AUTOSAR XML (schema 4-0-3)
standard types defined: Boolean, UInt16, UInt32
package /AUTOSAR_Platform/DataConstrs
  range DC_Boolean: raw 0..1
  range DC_UInt16: raw 0..65535
package /PATAC/Facility/DataTypes/Implementation
  compu method COMPU_Boolean: 0=FALSE, 1=TRUE
  unit NoUnit: factor-si-to-unit=1, offset-si-to-unit=0
package /PATAC/MSM/ComponentTypes
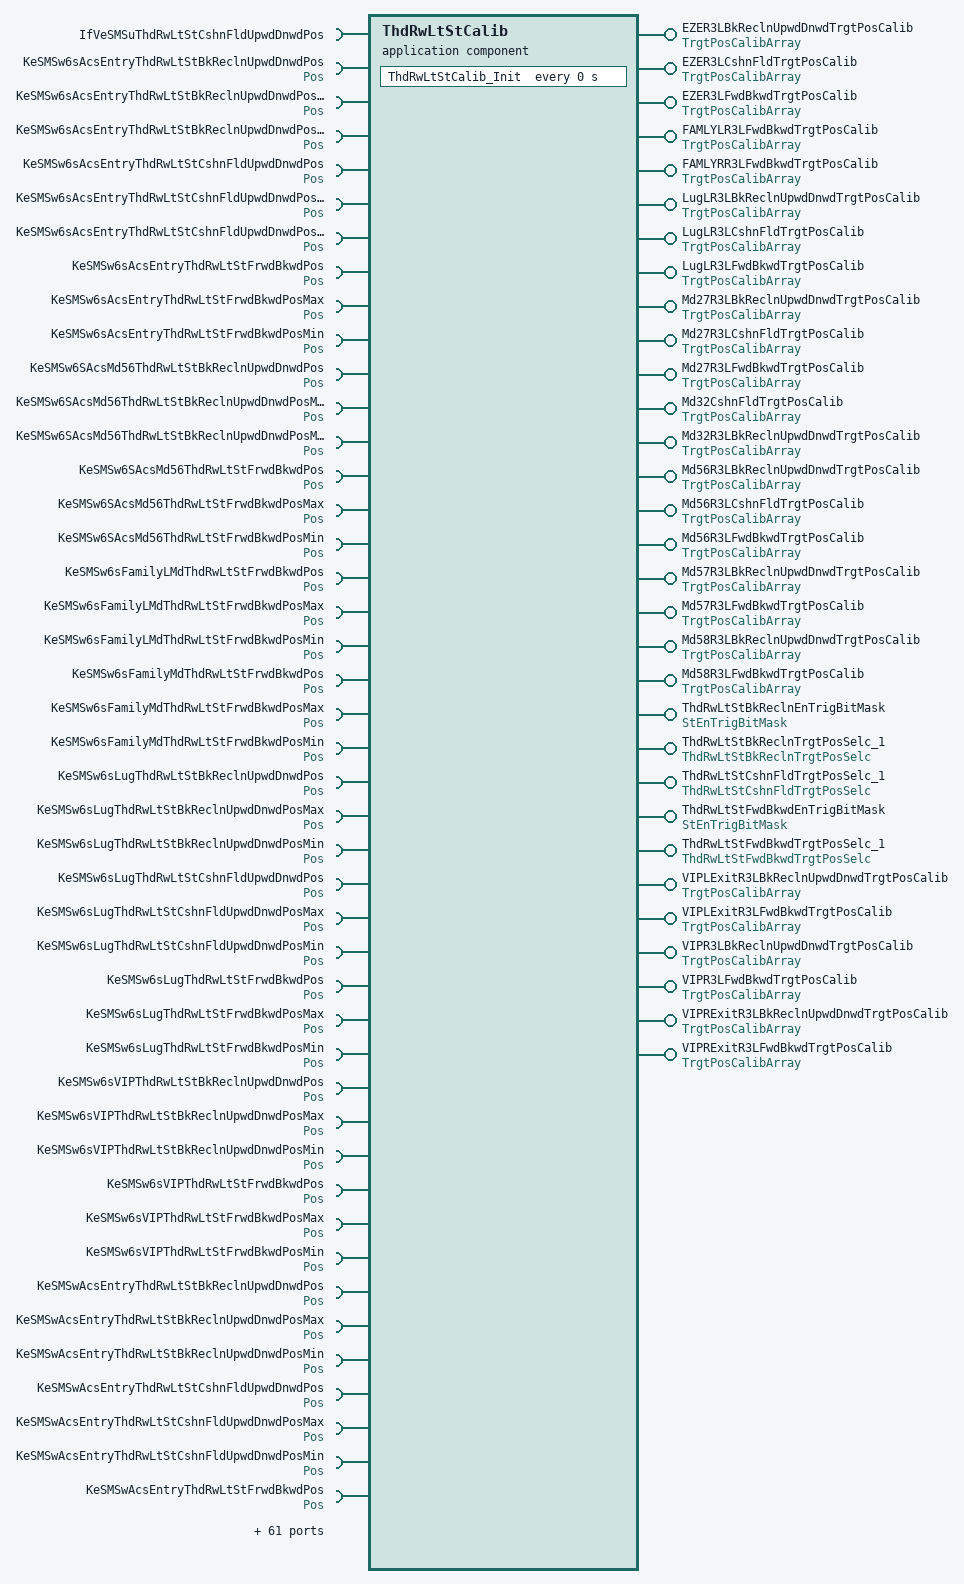
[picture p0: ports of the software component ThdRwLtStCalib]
  application sw component type ThdRwLtStCalib
    31 x provide port:
      EZER3LBkReclnUpwdDnwdTrgtPosCalib: nonqueued-sender-com-spec{data-element=TrgtPosArray, init-value=[4095, 4095, 4095]}, provided-interface=TrgtPosCalibArray
      EZER3LCshnFldTrgtPosCalib: nonqueued-sender-com-spec{data-element=TrgtPosArray, init-value=[4095, 4095, 4095]}, provided-interface=TrgtPosCalibArray
      EZER3LFwdBkwdTrgtPosCalib: nonqueued-sender-com-spec{data-element=TrgtPosArray, init-value=[4095, 4095, 4095]}, provided-interface=TrgtPosCalibArray
      FAMLYLR3LFwdBkwdTrgtPosCalib: nonqueued-sender-com-spec{data-element=TrgtPosArray, init-value=[4095, 4095, 4095]}, provided-interface=TrgtPosCalibArray
      FAMLYRR3LFwdBkwdTrgtPosCalib: nonqueued-sender-com-spec{data-element=TrgtPosArray, init-value=[4095, 4095, 4095]}, provided-interface=TrgtPosCalibArray
      LugLR3LBkReclnUpwdDnwdTrgtPosCalib: nonqueued-sender-com-spec{data-element=TrgtPosArray, init-value=[4095, 4095, 4095]}, provided-interface=TrgtPosCalibArray
      LugLR3LCshnFldTrgtPosCalib: nonqueued-sender-com-spec{data-element=TrgtPosArray, init-value=[4095, 4095, 4095]}, provided-interface=TrgtPosCalibArray
      LugLR3LFwdBkwdTrgtPosCalib: nonqueued-sender-com-spec{data-element=TrgtPosArray, init-value=[4095, 4095, 4095]}, provided-interface=TrgtPosCalibArray
      Md27R3LBkReclnUpwdDnwdTrgtPosCalib: nonqueued-sender-com-spec{data-element=TrgtPosArray, init-value=[4095, 4095, 4095]}, provided-interface=TrgtPosCalibArray
      Md27R3LCshnFldTrgtPosCalib: nonqueued-sender-com-spec{data-element=TrgtPosArray, init-value=[4095, 4095, 4095]}, provided-interface=TrgtPosCalibArray
      Md27R3LFwdBkwdTrgtPosCalib: nonqueued-sender-com-spec{data-element=TrgtPosArray, init-value=[4095, 4095, 4095]}, provided-interface=TrgtPosCalibArray
      Md32CshnFldTrgtPosCalib: nonqueued-sender-com-spec{data-element=TrgtPosArray, init-value=[4095, 4095, 4095]}, provided-interface=TrgtPosCalibArray
      Md32R3LBkReclnUpwdDnwdTrgtPosCalib: nonqueued-sender-com-spec{data-element=TrgtPosArray, init-value=[4095, 4095, 4095]}, provided-interface=TrgtPosCalibArray
      Md56R3LBkReclnUpwdDnwdTrgtPosCalib: nonqueued-sender-com-spec{data-element=TrgtPosArray, init-value=[4095, 4095, 4095]}, provided-interface=TrgtPosCalibArray
      Md56R3LCshnFldTrgtPosCalib: nonqueued-sender-com-spec{data-element=TrgtPosArray, init-value=[4095, 4095, 4095]}, provided-interface=TrgtPosCalibArray
      Md56R3LFwdBkwdTrgtPosCalib: nonqueued-sender-com-spec{data-element=TrgtPosArray, init-value=[4095, 4095, 4095]}, provided-interface=TrgtPosCalibArray
      Md57R3LBkReclnUpwdDnwdTrgtPosCalib: nonqueued-sender-com-spec{data-element=TrgtPosArray, init-value=[4095, 4095, 4095]}, provided-interface=TrgtPosCalibArray
      Md57R3LFwdBkwdTrgtPosCalib: nonqueued-sender-com-spec{data-element=TrgtPosArray, init-value=[4095, 4095, 4095]}, provided-interface=TrgtPosCalibArray
      Md58R3LBkReclnUpwdDnwdTrgtPosCalib: nonqueued-sender-com-spec{data-element=TrgtPosArray, init-value=[4095, 4095, 4095]}, provided-interface=TrgtPosCalibArray
      Md58R3LFwdBkwdTrgtPosCalib: nonqueued-sender-com-spec{data-element=TrgtPosArray, init-value=[4095, 4095, 4095]}, provided-interface=TrgtPosCalibArray
      ThdRwLtStBkReclnEnTrigBitMask: nonqueued-sender-com-spec{data-element=StEnTrigBitMask/Val, init-value=0}, provided-interface=StEnTrigBitMask
      ThdRwLtStBkReclnTrgtPosSelc_1: server-com-spec{operation=ThdRwLtStBkReclnTrgtPosSelc/Cal, queue-length=1}, provided-interface=ThdRwLtStBkReclnTrgtPosSelc
      ThdRwLtStCshnFldTrgtPosSelc_1: server-com-spec{operation=ThdRwLtStCshnFldTrgtPosSelc/Cal, queue-length=1}, provided-interface=ThdRwLtStCshnFldTrgtPosSelc
      ThdRwLtStFwdBkwdEnTrigBitMask: nonqueued-sender-com-spec{data-element=StEnTrigBitMask/Val, init-value=0}, provided-interface=StEnTrigBitMask
      ThdRwLtStFwdBkwdTrgtPosSelc_1: server-com-spec{operation=ThdRwLtStFwdBkwdTrgtPosSelc/Cal, queue-length=1}, provided-interface=ThdRwLtStFwdBkwdTrgtPosSelc
      VIPLExitR3LBkReclnUpwdDnwdTrgtPosCalib: nonqueued-sender-com-spec{data-element=TrgtPosArray, init-value=[4095, 4095, 4095]}, provided-interface=TrgtPosCalibArray
      VIPLExitR3LFwdBkwdTrgtPosCalib: nonqueued-sender-com-spec{data-element=TrgtPosArray, init-value=[4095, 4095, 4095]}, provided-interface=TrgtPosCalibArray
      VIPR3LBkReclnUpwdDnwdTrgtPosCalib: nonqueued-sender-com-spec{data-element=TrgtPosArray, init-value=[4095, 4095, 4095]}, provided-interface=TrgtPosCalibArray
      VIPR3LFwdBkwdTrgtPosCalib: nonqueued-sender-com-spec{data-element=TrgtPosArray, init-value=[4095, 4095, 4095]}, provided-interface=TrgtPosCalibArray
      VIPRExitR3LBkReclnUpwdDnwdTrgtPosCalib: nonqueued-sender-com-spec{data-element=TrgtPosArray, init-value=[4095, 4095, 4095]}, provided-interface=TrgtPosCalibArray
      VIPRExitR3LFwdBkwdTrgtPosCalib: nonqueued-sender-com-spec{data-element=TrgtPosArray, init-value=[4095, 4095, 4095]}, provided-interface=TrgtPosCalibArray
    105 x require port:
      IfVeSMSuThdRwLtStCshnFldUpwdDnwdPos: nonqueued-receiver-com-spec{data-element=IfVeSMSuThdRwLtStCshnFldUpwdDnwdPos/Val, filter=data-filter-type=ALWAYS, init-value=0}, required-interface=IfVeSMSuThdRwLtStCshnFldUpwdDnwdPos
      KeSMSw6sAcsEntryThdRwLtStBkReclnUpwdDnwdPos: parameter-require-com-spec{init-value=2080, parameter=Pos/Val}, required-interface=Pos
      KeSMSw6sAcsEntryThdRwLtStBkReclnUpwdDnwdPosMax: parameter-require-com-spec{init-value=2095, parameter=Pos/Val}, required-interface=Pos
      KeSMSw6sAcsEntryThdRwLtStBkReclnUpwdDnwdPosMin: parameter-require-com-spec{init-value=0, parameter=Pos/Val}, required-interface=Pos
      KeSMSw6sAcsEntryThdRwLtStCshnFldUpwdDnwdPos: parameter-require-com-spec{init-value=0, parameter=Pos/Val}, required-interface=Pos
      KeSMSw6sAcsEntryThdRwLtStCshnFldUpwdDnwdPosMax: parameter-require-com-spec{init-value=0, parameter=Pos/Val}, required-interface=Pos
      KeSMSw6sAcsEntryThdRwLtStCshnFldUpwdDnwdPosMin: parameter-require-com-spec{init-value=0, parameter=Pos/Val}, required-interface=Pos
      KeSMSw6sAcsEntryThdRwLtStFrwdBkwdPos: parameter-require-com-spec{init-value=2760, parameter=Pos/Val}, required-interface=Pos
      KeSMSw6sAcsEntryThdRwLtStFrwdBkwdPosMax: parameter-require-com-spec{init-value=4000, parameter=Pos/Val}, required-interface=Pos
      KeSMSw6sAcsEntryThdRwLtStFrwdBkwdPosMin: parameter-require-com-spec{init-value=2760, parameter=Pos/Val}, required-interface=Pos
      KeSMSw6SAcsMd56ThdRwLtStBkReclnUpwdDnwdPos: parameter-require-com-spec{init-value=0, parameter=Pos/Val}, required-interface=Pos
      KeSMSw6SAcsMd56ThdRwLtStBkReclnUpwdDnwdPosMax: parameter-require-com-spec{init-value=0, parameter=Pos/Val}, required-interface=Pos
      KeSMSw6SAcsMd56ThdRwLtStBkReclnUpwdDnwdPosMin: parameter-require-com-spec{init-value=0, parameter=Pos/Val}, required-interface=Pos
      KeSMSw6SAcsMd56ThdRwLtStFrwdBkwdPos: parameter-require-com-spec{init-value=0, parameter=Pos/Val}, required-interface=Pos
      KeSMSw6SAcsMd56ThdRwLtStFrwdBkwdPosMax: parameter-require-com-spec{init-value=0, parameter=Pos/Val}, required-interface=Pos
      KeSMSw6SAcsMd56ThdRwLtStFrwdBkwdPosMin: parameter-require-com-spec{init-value=0, parameter=Pos/Val}, required-interface=Pos
      KeSMSw6sFamilyLMdThdRwLtStFrwdBkwdPos: parameter-require-com-spec{init-value=0, parameter=Pos/Val}, required-interface=Pos
      KeSMSw6sFamilyLMdThdRwLtStFrwdBkwdPosMax: parameter-require-com-spec{init-value=0, parameter=Pos/Val}, required-interface=Pos
      KeSMSw6sFamilyLMdThdRwLtStFrwdBkwdPosMin: parameter-require-com-spec{init-value=0, parameter=Pos/Val}, required-interface=Pos
      KeSMSw6sFamilyMdThdRwLtStFrwdBkwdPos: parameter-require-com-spec{init-value=0, parameter=Pos/Val}, required-interface=Pos
      KeSMSw6sFamilyMdThdRwLtStFrwdBkwdPosMax: parameter-require-com-spec{init-value=0, parameter=Pos/Val}, required-interface=Pos
      KeSMSw6sFamilyMdThdRwLtStFrwdBkwdPosMin: parameter-require-com-spec{init-value=0, parameter=Pos/Val}, required-interface=Pos
      KeSMSw6sLugThdRwLtStBkReclnUpwdDnwdPos: parameter-require-com-spec{init-value=0, parameter=Pos/Val}, required-interface=Pos
      KeSMSw6sLugThdRwLtStBkReclnUpwdDnwdPosMax: parameter-require-com-spec{init-value=0, parameter=Pos/Val}, required-interface=Pos
      KeSMSw6sLugThdRwLtStBkReclnUpwdDnwdPosMin: parameter-require-com-spec{init-value=0, parameter=Pos/Val}, required-interface=Pos
      KeSMSw6sLugThdRwLtStCshnFldUpwdDnwdPos: parameter-require-com-spec{init-value=30, parameter=Pos/Val}, required-interface=Pos
      KeSMSw6sLugThdRwLtStCshnFldUpwdDnwdPosMax: parameter-require-com-spec{init-value=40, parameter=Pos/Val}, required-interface=Pos
      KeSMSw6sLugThdRwLtStCshnFldUpwdDnwdPosMin: parameter-require-com-spec{init-value=20, parameter=Pos/Val}, required-interface=Pos
      KeSMSw6sLugThdRwLtStFrwdBkwdPos: parameter-require-com-spec{init-value=0, parameter=Pos/Val}, required-interface=Pos
      KeSMSw6sLugThdRwLtStFrwdBkwdPosMax: parameter-require-com-spec{init-value=0, parameter=Pos/Val}, required-interface=Pos
      KeSMSw6sLugThdRwLtStFrwdBkwdPosMin: parameter-require-com-spec{init-value=0, parameter=Pos/Val}, required-interface=Pos
      KeSMSw6sVIPThdRwLtStBkReclnUpwdDnwdPos: parameter-require-com-spec{init-value=0, parameter=Pos/Val}, required-interface=Pos
      KeSMSw6sVIPThdRwLtStBkReclnUpwdDnwdPosMax: parameter-require-com-spec{init-value=0, parameter=Pos/Val}, required-interface=Pos
      KeSMSw6sVIPThdRwLtStBkReclnUpwdDnwdPosMin: parameter-require-com-spec{init-value=0, parameter=Pos/Val}, required-interface=Pos
      KeSMSw6sVIPThdRwLtStFrwdBkwdPos: parameter-require-com-spec{init-value=4000, parameter=Pos/Val}, required-interface=Pos
      KeSMSw6sVIPThdRwLtStFrwdBkwdPosMax: parameter-require-com-spec{init-value=4000, parameter=Pos/Val}, required-interface=Pos
      KeSMSw6sVIPThdRwLtStFrwdBkwdPosMin: parameter-require-com-spec{init-value=4000, parameter=Pos/Val}, required-interface=Pos
      KeSMSwAcsEntryThdRwLtStBkReclnUpwdDnwdPos: parameter-require-com-spec{init-value=2080, parameter=Pos/Val}, required-interface=Pos
      KeSMSwAcsEntryThdRwLtStBkReclnUpwdDnwdPosMax: parameter-require-com-spec{init-value=2095, parameter=Pos/Val}, required-interface=Pos
      KeSMSwAcsEntryThdRwLtStBkReclnUpwdDnwdPosMin: parameter-require-com-spec{init-value=0, parameter=Pos/Val}, required-interface=Pos
      KeSMSwAcsEntryThdRwLtStCshnFldUpwdDnwdPos: parameter-require-com-spec{init-value=0, parameter=Pos/Val}, required-interface=Pos
      KeSMSwAcsEntryThdRwLtStCshnFldUpwdDnwdPosMax: parameter-require-com-spec{init-value=0, parameter=Pos/Val}, required-interface=Pos
      KeSMSwAcsEntryThdRwLtStCshnFldUpwdDnwdPosMin: parameter-require-com-spec{init-value=0, parameter=Pos/Val}, required-interface=Pos
      KeSMSwAcsEntryThdRwLtStFrwdBkwdPos: parameter-require-com-spec{init-value=2760, parameter=Pos/Val}, required-interface=Pos
      KeSMSwAcsEntryThdRwLtStFrwdBkwdPosMax: parameter-require-com-spec{init-value=4000, parameter=Pos/Val}, required-interface=Pos
      KeSMSwAcsEntryThdRwLtStFrwdBkwdPosMin: parameter-require-com-spec{init-value=2760, parameter=Pos/Val}, required-interface=Pos
      KeSMSwAcsMd32ThdRwLtBkReclnUpwdDnwdPos: parameter-require-com-spec{init-value=2080, parameter=Pos/Val}, required-interface=Pos
      KeSMSwAcsMd32ThdRwLtBkReclnUpwdDnwdPosMax: parameter-require-com-spec{init-value=2080, parameter=Pos/Val}, required-interface=Pos
      KeSMSwAcsMd32ThdRwLtBkReclnUpwdDnwdPosMin: parameter-require-com-spec{init-value=2080, parameter=Pos/Val}, required-interface=Pos
      KeSMSwAcsMd32ThdRwLtFldUpwdDnwdPos: parameter-require-com-spec{init-value=0, parameter=Pos/Val}, required-interface=Pos
      KeSMSwAcsMd32ThdRwLtFldUpwdDnwdPosMax: parameter-require-com-spec{init-value=0, parameter=Pos/Val}, required-interface=Pos
      KeSMSwAcsMd32ThdRwLtFldUpwdDnwdPosMin: parameter-require-com-spec{init-value=0, parameter=Pos/Val}, required-interface=Pos
      KeSMSwAcsMd56ThdRwLtStBkReclnUpwdDnwdPos: parameter-require-com-spec{init-value=0, parameter=Pos/Val}, required-interface=Pos
      KeSMSwAcsMd56ThdRwLtStBkReclnUpwdDnwdPosMax: parameter-require-com-spec{init-value=0, parameter=Pos/Val}, required-interface=Pos
      KeSMSwAcsMd56ThdRwLtStBkReclnUpwdDnwdPosMin: parameter-require-com-spec{init-value=0, parameter=Pos/Val}, required-interface=Pos
      KeSMSwAcsMd56ThdRwLtStCshnFldUpwdDnwdPos: parameter-require-com-spec{init-value=0, parameter=Pos/Val}, required-interface=Pos
      KeSMSwAcsMd56ThdRwLtStCshnFldUpwdDnwdPosMax: parameter-require-com-spec{init-value=0, parameter=Pos/Val}, required-interface=Pos
      KeSMSwAcsMd56ThdRwLtStCshnFldUpwdDnwdPosMin: parameter-require-com-spec{init-value=0, parameter=Pos/Val}, required-interface=Pos
      KeSMSwAcsMd56ThdRwLtStFrwdBkwdPos: parameter-require-com-spec{init-value=0, parameter=Pos/Val}, required-interface=Pos
      KeSMSwAcsMd56ThdRwLtStFrwdBkwdPosMax: parameter-require-com-spec{init-value=0, parameter=Pos/Val}, required-interface=Pos
      KeSMSwAcsMd56ThdRwLtStFrwdBkwdPosMin: parameter-require-com-spec{init-value=0, parameter=Pos/Val}, required-interface=Pos
      KeSMSwAcsMd57ThdRwLtStBkReclnUpwdDnwdPos: parameter-require-com-spec{init-value=0, parameter=Pos/Val}, required-interface=Pos
      KeSMSwAcsMd57ThdRwLtStBkReclnUpwdDnwdPosMax: parameter-require-com-spec{init-value=0, parameter=Pos/Val}, required-interface=Pos
      KeSMSwAcsMd57ThdRwLtStBkReclnUpwdDnwdPosMin: parameter-require-com-spec{init-value=0, parameter=Pos/Val}, required-interface=Pos
      KeSMSwAcsMd57ThdRwLtStFrwdBkwdPos: parameter-require-com-spec{init-value=0, parameter=Pos/Val}, required-interface=Pos
      KeSMSwAcsMd57ThdRwLtStFrwdBkwdPosMax: parameter-require-com-spec{init-value=0, parameter=Pos/Val}, required-interface=Pos
      KeSMSwAcsMd57ThdRwLtStFrwdBkwdPosMin: parameter-require-com-spec{init-value=0, parameter=Pos/Val}, required-interface=Pos
      KeSMSwAcsMd6ThdRwLtStBkReclnUpwdDnwdPos: parameter-require-com-spec{init-value=0, parameter=Pos/Val}, required-interface=Pos
      KeSMSwAcsMd6ThdRwLtStBkReclnUpwdDnwdPosMax: parameter-require-com-spec{init-value=0, parameter=Pos/Val}, required-interface=Pos
      KeSMSwAcsMd6ThdRwLtStBkReclnUpwdDnwdPosMin: parameter-require-com-spec{init-value=0, parameter=Pos/Val}, required-interface=Pos
      KeSMSwAcsMd6ThdRwLtStCshnFldUpwdDnwdPos: parameter-require-com-spec{init-value=0, parameter=Pos/Val}, required-interface=Pos
      KeSMSwAcsMd6ThdRwLtStCshnFldUpwdDnwdPosMax: parameter-require-com-spec{init-value=0, parameter=Pos/Val}, required-interface=Pos
      KeSMSwAcsMd6ThdRwLtStCshnFldUpwdDnwdPosMin: parameter-require-com-spec{init-value=0, parameter=Pos/Val}, required-interface=Pos
      KeSMSwAcsMd6ThdRwLtStFrwdBkwdPos: parameter-require-com-spec{init-value=0, parameter=Pos/Val}, required-interface=Pos
      KeSMSwAcsMd6ThdRwLtStFrwdBkwdPosMax: parameter-require-com-spec{init-value=0, parameter=Pos/Val}, required-interface=Pos
      KeSMSwAcsMd6ThdRwLtStFrwdBkwdPosMin: parameter-require-com-spec{init-value=0, parameter=Pos/Val}, required-interface=Pos
      KeSMSwFamilyLMdThdRwLtStFrwdBkwdPos: parameter-require-com-spec{init-value=0, parameter=Pos/Val}, required-interface=Pos
      KeSMSwFamilyLMdThdRwLtStFrwdBkwdPosMax: parameter-require-com-spec{init-value=0, parameter=Pos/Val}, required-interface=Pos
      KeSMSwFamilyLMdThdRwLtStFrwdBkwdPosMin: parameter-require-com-spec{init-value=0, parameter=Pos/Val}, required-interface=Pos
      KeSMSwFamilyMdThdRwLtStFrwdBkwdPos: parameter-require-com-spec{init-value=0, parameter=Pos/Val}, required-interface=Pos
      KeSMSwFamilyMdThdRwLtStFrwdBkwdPosMax: parameter-require-com-spec{init-value=0, parameter=Pos/Val}, required-interface=Pos
      KeSMSwFamilyMdThdRwLtStFrwdBkwdPosMin: parameter-require-com-spec{init-value=0, parameter=Pos/Val}, required-interface=Pos
      KeSMSwLugThdRwLtStBkReclnUpwdDnwdPos: parameter-require-com-spec{init-value=0, parameter=Pos/Val}, required-interface=Pos
      KeSMSwLugThdRwLtStBkReclnUpwdDnwdPosMax: parameter-require-com-spec{init-value=0, parameter=Pos/Val}, required-interface=Pos
      KeSMSwLugThdRwLtStBkReclnUpwdDnwdPosMin: parameter-require-com-spec{init-value=0, parameter=Pos/Val}, required-interface=Pos
      KeSMSwLugThdRwLtStCshnFldUpwdDnwdPos: parameter-require-com-spec{init-value=30, parameter=Pos/Val}, required-interface=Pos
      KeSMSwLugThdRwLtStCshnFldUpwdDnwdPosMax: parameter-require-com-spec{init-value=0, parameter=Pos/Val}, required-interface=Pos
      KeSMSwLugThdRwLtStCshnFldUpwdDnwdPosMin: parameter-require-com-spec{init-value=20, parameter=Pos/Val}, required-interface=Pos
      KeSMSwLugThdRwLtStFrwdBkwdPos: parameter-require-com-spec{init-value=0, parameter=Pos/Val}, required-interface=Pos
      KeSMSwLugThdRwLtStFrwdBkwdPosMax: parameter-require-com-spec{init-value=0, parameter=Pos/Val}, required-interface=Pos
      KeSMSwLugThdRwLtStFrwdBkwdPosMin: parameter-require-com-spec{init-value=0, parameter=Pos/Val}, required-interface=Pos
      KeSMSwThdRwLtStBkReclnEnTrigBitMask: parameter-require-com-spec{init-value=6153, parameter=StEnTrigBitMask/Val}, required-interface=StEnTrigBitMask
      KeSMSwThdRwLtStBkReclnEnTrigBitMask6s: parameter-require-com-spec{init-value=6153, parameter=StEnTrigBitMask/Val}, required-interface=StEnTrigBitMask
      KeSMSwThdRwLtStFwdBkwdEnTrigBitMask: parameter-require-com-spec{init-value=6153, parameter=StEnTrigBitMask/Val}, required-interface=StEnTrigBitMask
      KeSMSwThdRwLtStFwdBkwdEnTrigBitMask6s: parameter-require-com-spec{init-value=6153, parameter=StEnTrigBitMask/Val}, required-interface=StEnTrigBitMask
      KeSMSwVIPThdRwLtStBkReclnUpwdDnwdPos: parameter-require-com-spec{init-value=0, parameter=Pos/Val}, required-interface=Pos
      KeSMSwVIPThdRwLtStBkReclnUpwdDnwdPosMax: parameter-require-com-spec{init-value=0, parameter=Pos/Val}, required-interface=Pos
      KeSMSwVIPThdRwLtStBkReclnUpwdDnwdPosMin: parameter-require-com-spec{init-value=0, parameter=Pos/Val}, required-interface=Pos
      KeSMSwVIPThdRwLtStFrwdBkwdPos: parameter-require-com-spec{init-value=4000, parameter=Pos/Val}, required-interface=Pos
      KeSMSwVIPThdRwLtStFrwdBkwdPosMax: parameter-require-com-spec{init-value=4000, parameter=Pos/Val}, required-interface=Pos
      KeSMSwVIPThdRwLtStFrwdBkwdPosMin: parameter-require-com-spec{init-value=4000, parameter=Pos/Val}, required-interface=Pos
      Md58TrgtPos: required-com-specs=[Md58TrgtPos/Get, Md58TrgtPos/Set], required-interface=Md58TrgtPos
      StNumFlg: required-interface=StNumFlg
        required-com-specs:
          data-element=Is4s, filter=data-filter-type=ALWAYS, init-value=0
          data-element=Is6s, filter=data-filter-type=ALWAYS, init-value=0
          data-element=Is6s7s, filter=data-filter-type=ALWAYS, init-value=0
          data-element=Is7s, filter=data-filter-type=ALWAYS, init-value=0
      VIPLExit557TrgtPos: required-com-specs=[VIPLExit557TrgtPos/Get, VIPLExit557TrgtPos/Set], required-interface=VIPLExit557TrgtPos
      VIPRExit557TrgtPos: required-com-specs=[VIPRExit557TrgtPos/Get, VIPRExit557TrgtPos/Set], required-interface=VIPRExit557TrgtPos
    behavior ThdRwLtStCalib_InternalBehavior
      operation invoked event OIT_ThdRwLtStBkReclnTrgtPosSelc_1_Cal_ThdRwLtStBkReclnTrgtPosSelc_1_Cal: start-on-event=ThdRwLtStBkReclnTrgtPosSelc_1_Cal, operation=ThdRwLtStBkReclnTrgtPosSelc_1.Cal
      timing event ThdRwLtStCalib_InitEvent: start-on-event=ThdRwLtStCalib_Init, period=0
      operation invoked event OIT_ThdRwLtStCshnFldTrgtPosSelc_1_Cal_ThdRwLtStCshnFldTrgtPosSelc_1_Cal: start-on-event=ThdRwLtStCshnFldTrgtPosSelc_1_Cal, operation=ThdRwLtStCshnFldTrgtPosSelc_1.Cal
      operation invoked event OIT_ThdRwLtStFwdBkwdTrgtPosSelc_1_Cal_ThdRwLtStFwdBkwdTrgtPosSelc_1_Cal: start-on-event=ThdRwLtStFwdBkwdTrgtPosSelc_1_Cal, operation=ThdRwLtStFwdBkwdTrgtPosSelc_1.Cal
      4 x runnable:
        ThdRwLtStBkReclnTrgtPosSelc_1_Cal
          data-receive-point-by-arguments:
            4 x access:
              REC_StNumFlg_Is4s: accessed-variable=StNumFlg.Is4s
              REC_StNumFlg_Is6s: accessed-variable=StNumFlg.Is6s
              REC_StNumFlg_Is6s7s: accessed-variable=StNumFlg.Is6s7s
              REC_StNumFlg_Is7s: accessed-variable=StNumFlg.Is7s
          data-send-points:
            14 x access:
              SEND_EZER3LBkReclnUpwdDnwdTrgtPosCalib_TrgtPosArray: accessed-variable=EZER3LBkReclnUpwdDnwdTrgtPosCalib.TrgtPosArray
              SEND_LugLR3LBkReclnUpwdDnwdTrgtPosCalib_TrgtPosArray: accessed-variable=LugLR3LBkReclnUpwdDnwdTrgtPosCalib.TrgtPosArray
              SEND_Md27R3LBkReclnUpwdDnwdTrgtPosCalib_TrgtPosArray: accessed-variable=Md27R3LBkReclnUpwdDnwdTrgtPosCalib.TrgtPosArray
              SEND_Md32R3LBkReclnUpwdDnwdTrgtPosCalib_TrgtPosArray: accessed-variable=Md32R3LBkReclnUpwdDnwdTrgtPosCalib.TrgtPosArray
              SEND_Md{56..58}R3LBkReclnUpwdDnwdTrgtPosCalib_TrgtPosArray: accessed-variable=Md{56..58}R3LBkReclnUpwdDnwdTrgtPosCalib.TrgtPosArray
              SEND_Md58R3LFwdBkwdTrgtPosCalib_TrgtPosArray: accessed-variable=Md58R3LFwdBkwdTrgtPosCalib.TrgtPosArray
              SEND_ThdRwLtStBkReclnEnTrigBitMask_Val: accessed-variable=ThdRwLtStBkReclnEnTrigBitMask.Val
              SEND_VIPLExitR3LBkReclnUpwdDnwdTrgtPosCalib_TrgtPosArray: accessed-variable=VIPLExitR3LBkReclnUpwdDnwdTrgtPosCalib.TrgtPosArray
              SEND_VIPLExitR3LFwdBkwdTrgtPosCalib_TrgtPosArray: accessed-variable=VIPLExitR3LFwdBkwdTrgtPosCalib.TrgtPosArray
              SEND_VIPR3LBkReclnUpwdDnwdTrgtPosCalib_TrgtPosArray: accessed-variable=VIPR3LBkReclnUpwdDnwdTrgtPosCalib.TrgtPosArray
              SEND_VIPRExitR3LBkReclnUpwdDnwdTrgtPosCalib_TrgtPosArray: accessed-variable=VIPRExitR3LBkReclnUpwdDnwdTrgtPosCalib.TrgtPosArray
              SEND_VIPRExitR3LFwdBkwdTrgtPosCalib_TrgtPosArray: accessed-variable=VIPRExitR3LFwdBkwdTrgtPosCalib.TrgtPosArray
          100 x parameter access:
            PA_KeSMSw6sAcsEntryThdRwLtStBkReclnUpwdDnwdPos_Val: accessed-parameter=KeSMSw6sAcsEntryThdRwLtStBkReclnUpwdDnwdPos.Val
            PA_KeSMSw6sAcsEntryThdRwLtStBkReclnUpwdDnwdPosMax_Val: accessed-parameter=KeSMSw6sAcsEntryThdRwLtStBkReclnUpwdDnwdPosMax.Val
            PA_KeSMSw6sAcsEntryThdRwLtStBkReclnUpwdDnwdPosMin_Val: accessed-parameter=KeSMSw6sAcsEntryThdRwLtStBkReclnUpwdDnwdPosMin.Val
            PA_KeSMSw6sAcsEntryThdRwLtStCshnFldUpwdDnwdPos_Val: accessed-parameter=KeSMSw6sAcsEntryThdRwLtStCshnFldUpwdDnwdPos.Val
            PA_KeSMSw6sAcsEntryThdRwLtStCshnFldUpwdDnwdPosMax_Val: accessed-parameter=KeSMSw6sAcsEntryThdRwLtStCshnFldUpwdDnwdPosMax.Val
            PA_KeSMSw6sAcsEntryThdRwLtStCshnFldUpwdDnwdPosMin_Val: accessed-parameter=KeSMSw6sAcsEntryThdRwLtStCshnFldUpwdDnwdPosMin.Val
            PA_KeSMSw6sAcsEntryThdRwLtStFrwdBkwdPos_Val: accessed-parameter=KeSMSw6sAcsEntryThdRwLtStFrwdBkwdPos.Val
            PA_KeSMSw6sAcsEntryThdRwLtStFrwdBkwdPosMax_Val: accessed-parameter=KeSMSw6sAcsEntryThdRwLtStFrwdBkwdPosMax.Val
            PA_KeSMSw6sAcsEntryThdRwLtStFrwdBkwdPosMin_Val: accessed-parameter=KeSMSw6sAcsEntryThdRwLtStFrwdBkwdPosMin.Val
            PA_KeSMSw6SAcsMd56ThdRwLtStBkReclnUpwdDnwdPos_Val: accessed-parameter=KeSMSw6SAcsMd56ThdRwLtStBkReclnUpwdDnwdPos.Val
            PA_KeSMSw6SAcsMd56ThdRwLtStBkReclnUpwdDnwdPosMax_Val: accessed-parameter=KeSMSw6SAcsMd56ThdRwLtStBkReclnUpwdDnwdPosMax.Val
            PA_KeSMSw6SAcsMd56ThdRwLtStBkReclnUpwdDnwdPosMin_Val: accessed-parameter=KeSMSw6SAcsMd56ThdRwLtStBkReclnUpwdDnwdPosMin.Val
            PA_KeSMSw6SAcsMd56ThdRwLtStFrwdBkwdPos_Val: accessed-parameter=KeSMSw6SAcsMd56ThdRwLtStFrwdBkwdPos.Val
            PA_KeSMSw6SAcsMd56ThdRwLtStFrwdBkwdPosMax_Val: accessed-parameter=KeSMSw6SAcsMd56ThdRwLtStFrwdBkwdPosMax.Val
            PA_KeSMSw6SAcsMd56ThdRwLtStFrwdBkwdPosMin_Val: accessed-parameter=KeSMSw6SAcsMd56ThdRwLtStFrwdBkwdPosMin.Val
            PA_KeSMSw6sFamilyLMdThdRwLtStFrwdBkwdPos_Val: accessed-parameter=KeSMSw6sFamilyLMdThdRwLtStFrwdBkwdPos.Val
            PA_KeSMSw6sFamilyLMdThdRwLtStFrwdBkwdPosMax_Val: accessed-parameter=KeSMSw6sFamilyLMdThdRwLtStFrwdBkwdPosMax.Val
            PA_KeSMSw6sFamilyLMdThdRwLtStFrwdBkwdPosMin_Val: accessed-parameter=KeSMSw6sFamilyLMdThdRwLtStFrwdBkwdPosMin.Val
            PA_KeSMSw6sFamilyMdThdRwLtStFrwdBkwdPos_Val: accessed-parameter=KeSMSw6sFamilyMdThdRwLtStFrwdBkwdPos.Val
            PA_KeSMSw6sFamilyMdThdRwLtStFrwdBkwdPosMax_Val: accessed-parameter=KeSMSw6sFamilyMdThdRwLtStFrwdBkwdPosMax.Val
            PA_KeSMSw6sFamilyMdThdRwLtStFrwdBkwdPosMin_Val: accessed-parameter=KeSMSw6sFamilyMdThdRwLtStFrwdBkwdPosMin.Val
            PA_KeSMSw6sLugThdRwLtStBkReclnUpwdDnwdPos_Val: accessed-parameter=KeSMSw6sLugThdRwLtStBkReclnUpwdDnwdPos.Val
            PA_KeSMSw6sLugThdRwLtStBkReclnUpwdDnwdPosMax_Val: accessed-parameter=KeSMSw6sLugThdRwLtStBkReclnUpwdDnwdPosMax.Val
            PA_KeSMSw6sLugThdRwLtStBkReclnUpwdDnwdPosMin_Val: accessed-parameter=KeSMSw6sLugThdRwLtStBkReclnUpwdDnwdPosMin.Val
            PA_KeSMSw6sLugThdRwLtStCshnFldUpwdDnwdPos_Val: accessed-parameter=KeSMSw6sLugThdRwLtStCshnFldUpwdDnwdPos.Val
            PA_KeSMSw6sLugThdRwLtStCshnFldUpwdDnwdPosMax_Val: accessed-parameter=KeSMSw6sLugThdRwLtStCshnFldUpwdDnwdPosMax.Val
            PA_KeSMSw6sLugThdRwLtStCshnFldUpwdDnwdPosMin_Val: accessed-parameter=KeSMSw6sLugThdRwLtStCshnFldUpwdDnwdPosMin.Val
            PA_KeSMSw6sLugThdRwLtStFrwdBkwdPos_Val: accessed-parameter=KeSMSw6sLugThdRwLtStFrwdBkwdPos.Val
            PA_KeSMSw6sLugThdRwLtStFrwdBkwdPosMax_Val: accessed-parameter=KeSMSw6sLugThdRwLtStFrwdBkwdPosMax.Val
            PA_KeSMSw6sLugThdRwLtStFrwdBkwdPosMin_Val: accessed-parameter=KeSMSw6sLugThdRwLtStFrwdBkwdPosMin.Val
            PA_KeSMSw6sVIPThdRwLtStBkReclnUpwdDnwdPos_Val: accessed-parameter=KeSMSw6sVIPThdRwLtStBkReclnUpwdDnwdPos.Val
            PA_KeSMSw6sVIPThdRwLtStBkReclnUpwdDnwdPosMax_Val: accessed-parameter=KeSMSw6sVIPThdRwLtStBkReclnUpwdDnwdPosMax.Val
            PA_KeSMSw6sVIPThdRwLtStBkReclnUpwdDnwdPosMin_Val: accessed-parameter=KeSMSw6sVIPThdRwLtStBkReclnUpwdDnwdPosMin.Val
            PA_KeSMSw6sVIPThdRwLtStFrwdBkwdPos_Val: accessed-parameter=KeSMSw6sVIPThdRwLtStFrwdBkwdPos.Val
            PA_KeSMSw6sVIPThdRwLtStFrwdBkwdPosMax_Val: accessed-parameter=KeSMSw6sVIPThdRwLtStFrwdBkwdPosMax.Val
            PA_KeSMSw6sVIPThdRwLtStFrwdBkwdPosMin_Val: accessed-parameter=KeSMSw6sVIPThdRwLtStFrwdBkwdPosMin.Val
            PA_KeSMSwAcsEntryThdRwLtStBkReclnUpwdDnwdPos_Val: accessed-parameter=KeSMSwAcsEntryThdRwLtStBkReclnUpwdDnwdPos.Val
            PA_KeSMSwAcsEntryThdRwLtStBkReclnUpwdDnwdPosMax_Val: accessed-parameter=KeSMSwAcsEntryThdRwLtStBkReclnUpwdDnwdPosMax.Val
            PA_KeSMSwAcsEntryThdRwLtStBkReclnUpwdDnwdPosMin_Val: accessed-parameter=KeSMSwAcsEntryThdRwLtStBkReclnUpwdDnwdPosMin.Val
            PA_KeSMSwAcsEntryThdRwLtStCshnFldUpwdDnwdPos_Val: accessed-parameter=KeSMSwAcsEntryThdRwLtStCshnFldUpwdDnwdPos.Val
            PA_KeSMSwAcsEntryThdRwLtStCshnFldUpwdDnwdPosMax_Val: accessed-parameter=KeSMSwAcsEntryThdRwLtStCshnFldUpwdDnwdPosMax.Val
            PA_KeSMSwAcsEntryThdRwLtStCshnFldUpwdDnwdPosMin_Val: accessed-parameter=KeSMSwAcsEntryThdRwLtStCshnFldUpwdDnwdPosMin.Val
            PA_KeSMSwAcsEntryThdRwLtStFrwdBkwdPos_Val: accessed-parameter=KeSMSwAcsEntryThdRwLtStFrwdBkwdPos.Val
            PA_KeSMSwAcsEntryThdRwLtStFrwdBkwdPosMax_Val: accessed-parameter=KeSMSwAcsEntryThdRwLtStFrwdBkwdPosMax.Val
            PA_KeSMSwAcsEntryThdRwLtStFrwdBkwdPosMin_Val: accessed-parameter=KeSMSwAcsEntryThdRwLtStFrwdBkwdPosMin.Val
            PA_KeSMSwAcsMd32ThdRwLtBkReclnUpwdDnwdPos_Val: accessed-parameter=KeSMSwAcsMd32ThdRwLtBkReclnUpwdDnwdPos.Val
            PA_KeSMSwAcsMd32ThdRwLtBkReclnUpwdDnwdPosMax_Val: accessed-parameter=KeSMSwAcsMd32ThdRwLtBkReclnUpwdDnwdPosMax.Val
            PA_KeSMSwAcsMd32ThdRwLtBkReclnUpwdDnwdPosMin_Val: accessed-parameter=KeSMSwAcsMd32ThdRwLtBkReclnUpwdDnwdPosMin.Val
            PA_KeSMSwAcsMd32ThdRwLtFldUpwdDnwdPos_Val: accessed-parameter=KeSMSwAcsMd32ThdRwLtFldUpwdDnwdPos.Val
            PA_KeSMSwAcsMd32ThdRwLtFldUpwdDnwdPosMax_Val: accessed-parameter=KeSMSwAcsMd32ThdRwLtFldUpwdDnwdPosMax.Val
            PA_KeSMSwAcsMd32ThdRwLtFldUpwdDnwdPosMin_Val: accessed-parameter=KeSMSwAcsMd32ThdRwLtFldUpwdDnwdPosMin.Val
            PA_KeSMSwAcsMd56ThdRwLtStBkReclnUpwdDnwdPos_Val: accessed-parameter=KeSMSwAcsMd56ThdRwLtStBkReclnUpwdDnwdPos.Val
            PA_KeSMSwAcsMd56ThdRwLtStBkReclnUpwdDnwdPosMax_Val: accessed-parameter=KeSMSwAcsMd56ThdRwLtStBkReclnUpwdDnwdPosMax.Val
            PA_KeSMSwAcsMd56ThdRwLtStBkReclnUpwdDnwdPosMin_Val: accessed-parameter=KeSMSwAcsMd56ThdRwLtStBkReclnUpwdDnwdPosMin.Val
            PA_KeSMSwAcsMd56ThdRwLtStCshnFldUpwdDnwdPos_Val: accessed-parameter=KeSMSwAcsMd56ThdRwLtStCshnFldUpwdDnwdPos.Val
            PA_KeSMSwAcsMd56ThdRwLtStCshnFldUpwdDnwdPosMax_Val: accessed-parameter=KeSMSwAcsMd56ThdRwLtStCshnFldUpwdDnwdPosMax.Val
            PA_KeSMSwAcsMd56ThdRwLtStCshnFldUpwdDnwdPosMin_Val: accessed-parameter=KeSMSwAcsMd56ThdRwLtStCshnFldUpwdDnwdPosMin.Val
            PA_KeSMSwAcsMd56ThdRwLtStFrwdBkwdPos_Val: accessed-parameter=KeSMSwAcsMd56ThdRwLtStFrwdBkwdPos.Val
            PA_KeSMSwAcsMd56ThdRwLtStFrwdBkwdPosMax_Val: accessed-parameter=KeSMSwAcsMd56ThdRwLtStFrwdBkwdPosMax.Val
            PA_KeSMSwAcsMd56ThdRwLtStFrwdBkwdPosMin_Val: accessed-parameter=KeSMSwAcsMd56ThdRwLtStFrwdBkwdPosMin.Val
            PA_KeSMSwAcsMd57ThdRwLtStBkReclnUpwdDnwdPos_Val: accessed-parameter=KeSMSwAcsMd57ThdRwLtStBkReclnUpwdDnwdPos.Val
            PA_KeSMSwAcsMd57ThdRwLtStBkReclnUpwdDnwdPosMax_Val: accessed-parameter=KeSMSwAcsMd57ThdRwLtStBkReclnUpwdDnwdPosMax.Val
            PA_KeSMSwAcsMd57ThdRwLtStBkReclnUpwdDnwdPosMin_Val: accessed-parameter=KeSMSwAcsMd57ThdRwLtStBkReclnUpwdDnwdPosMin.Val
            PA_KeSMSwAcsMd57ThdRwLtStFrwdBkwdPos_Val: accessed-parameter=KeSMSwAcsMd57ThdRwLtStFrwdBkwdPos.Val
            PA_KeSMSwAcsMd57ThdRwLtStFrwdBkwdPosMax_Val: accessed-parameter=KeSMSwAcsMd57ThdRwLtStFrwdBkwdPosMax.Val
            PA_KeSMSwAcsMd57ThdRwLtStFrwdBkwdPosMin_Val: accessed-parameter=KeSMSwAcsMd57ThdRwLtStFrwdBkwdPosMin.Val
            PA_KeSMSwAcsMd6ThdRwLtStBkReclnUpwdDnwdPos_Val: accessed-parameter=KeSMSwAcsMd6ThdRwLtStBkReclnUpwdDnwdPos.Val
            PA_KeSMSwAcsMd6ThdRwLtStBkReclnUpwdDnwdPosMax_Val: accessed-parameter=KeSMSwAcsMd6ThdRwLtStBkReclnUpwdDnwdPosMax.Val
            PA_KeSMSwAcsMd6ThdRwLtStBkReclnUpwdDnwdPosMin_Val: accessed-parameter=KeSMSwAcsMd6ThdRwLtStBkReclnUpwdDnwdPosMin.Val
            PA_KeSMSwAcsMd6ThdRwLtStCshnFldUpwdDnwdPos_Val: accessed-parameter=KeSMSwAcsMd6ThdRwLtStCshnFldUpwdDnwdPos.Val
            PA_KeSMSwAcsMd6ThdRwLtStCshnFldUpwdDnwdPosMax_Val: accessed-parameter=KeSMSwAcsMd6ThdRwLtStCshnFldUpwdDnwdPosMax.Val
            PA_KeSMSwAcsMd6ThdRwLtStCshnFldUpwdDnwdPosMin_Val: accessed-parameter=KeSMSwAcsMd6ThdRwLtStCshnFldUpwdDnwdPosMin.Val
            PA_KeSMSwAcsMd6ThdRwLtStFrwdBkwdPos_Val: accessed-parameter=KeSMSwAcsMd6ThdRwLtStFrwdBkwdPos.Val
            PA_KeSMSwAcsMd6ThdRwLtStFrwdBkwdPosMax_Val: accessed-parameter=KeSMSwAcsMd6ThdRwLtStFrwdBkwdPosMax.Val
            PA_KeSMSwAcsMd6ThdRwLtStFrwdBkwdPosMin_Val: accessed-parameter=KeSMSwAcsMd6ThdRwLtStFrwdBkwdPosMin.Val
            PA_KeSMSwFamilyLMdThdRwLtStFrwdBkwdPos_Val: accessed-parameter=KeSMSwFamilyLMdThdRwLtStFrwdBkwdPos.Val
            PA_KeSMSwFamilyLMdThdRwLtStFrwdBkwdPosMax_Val: accessed-parameter=KeSMSwFamilyLMdThdRwLtStFrwdBkwdPosMax.Val
            PA_KeSMSwFamilyLMdThdRwLtStFrwdBkwdPosMin_Val: accessed-parameter=KeSMSwFamilyLMdThdRwLtStFrwdBkwdPosMin.Val
            PA_KeSMSwFamilyMdThdRwLtStFrwdBkwdPos_Val: accessed-parameter=KeSMSwFamilyMdThdRwLtStFrwdBkwdPos.Val
            PA_KeSMSwFamilyMdThdRwLtStFrwdBkwdPosMax_Val: accessed-parameter=KeSMSwFamilyMdThdRwLtStFrwdBkwdPosMax.Val
            PA_KeSMSwFamilyMdThdRwLtStFrwdBkwdPosMin_Val: accessed-parameter=KeSMSwFamilyMdThdRwLtStFrwdBkwdPosMin.Val
            PA_KeSMSwLugThdRwLtStBkReclnUpwdDnwdPos_Val: accessed-parameter=KeSMSwLugThdRwLtStBkReclnUpwdDnwdPos.Val
            PA_KeSMSwLugThdRwLtStBkReclnUpwdDnwdPosMax_Val: accessed-parameter=KeSMSwLugThdRwLtStBkReclnUpwdDnwdPosMax.Val
            PA_KeSMSwLugThdRwLtStBkReclnUpwdDnwdPosMin_Val: accessed-parameter=KeSMSwLugThdRwLtStBkReclnUpwdDnwdPosMin.Val
            PA_KeSMSwLugThdRwLtStCshnFldUpwdDnwdPos_Val: accessed-parameter=KeSMSwLugThdRwLtStCshnFldUpwdDnwdPos.Val
            PA_KeSMSwLugThdRwLtStCshnFldUpwdDnwdPosMax_Val: accessed-parameter=KeSMSwLugThdRwLtStCshnFldUpwdDnwdPosMax.Val
            PA_KeSMSwLugThdRwLtStCshnFldUpwdDnwdPosMin_Val: accessed-parameter=KeSMSwLugThdRwLtStCshnFldUpwdDnwdPosMin.Val
            PA_KeSMSwLugThdRwLtStFrwdBkwdPos_Val: accessed-parameter=KeSMSwLugThdRwLtStFrwdBkwdPos.Val
            PA_KeSMSwLugThdRwLtStFrwdBkwdPosMax_Val: accessed-parameter=KeSMSwLugThdRwLtStFrwdBkwdPosMax.Val
            PA_KeSMSwLugThdRwLtStFrwdBkwdPosMin_Val: accessed-parameter=KeSMSwLugThdRwLtStFrwdBkwdPosMin.Val
            PA_KeSMSwThdRwLtStBkReclnEnTrigBitMask_Val: accessed-parameter=KeSMSwThdRwLtStBkReclnEnTrigBitMask.Val
            PA_KeSMSwThdRwLtStBkReclnEnTrigBitMask6s_Val: accessed-parameter=KeSMSwThdRwLtStBkReclnEnTrigBitMask6s.Val
            PA_KeSMSwThdRwLtStFwdBkwdEnTrigBitMask_Val: accessed-parameter=KeSMSwThdRwLtStFwdBkwdEnTrigBitMask.Val
            PA_KeSMSwThdRwLtStFwdBkwdEnTrigBitMask6s_Val: accessed-parameter=KeSMSwThdRwLtStFwdBkwdEnTrigBitMask6s.Val
            PA_KeSMSwVIPThdRwLtStBkReclnUpwdDnwdPos_Val: accessed-parameter=KeSMSwVIPThdRwLtStBkReclnUpwdDnwdPos.Val
            PA_KeSMSwVIPThdRwLtStBkReclnUpwdDnwdPosMax_Val: accessed-parameter=KeSMSwVIPThdRwLtStBkReclnUpwdDnwdPosMax.Val
            PA_KeSMSwVIPThdRwLtStBkReclnUpwdDnwdPosMin_Val: accessed-parameter=KeSMSwVIPThdRwLtStBkReclnUpwdDnwdPosMin.Val
            PA_KeSMSwVIPThdRwLtStFrwdBkwdPos_Val: accessed-parameter=KeSMSwVIPThdRwLtStFrwdBkwdPos.Val
            PA_KeSMSwVIPThdRwLtStFrwdBkwdPosMax_Val: accessed-parameter=KeSMSwVIPThdRwLtStFrwdBkwdPosMax.Val
            PA_KeSMSwVIPThdRwLtStFrwdBkwdPosMin_Val: accessed-parameter=KeSMSwVIPThdRwLtStFrwdBkwdPosMin.Val
          sync call SC_Md58TrgtPos_Get: operation=Md58TrgtPos.Get, timeout=0
          sync call SC_VIPLExit557TrgtPos_Get: operation=VIPLExit557TrgtPos.Get, timeout=0
          sync call SC_VIPRExit557TrgtPos_Get: operation=VIPRExit557TrgtPos.Get, timeout=0
        ThdRwLtStCalib_Init
          100 x parameter access:
            PA_KeSMSw6sAcsEntryThdRwLtStBkReclnUpwdDnwdPos_Val: accessed-parameter=KeSMSw6sAcsEntryThdRwLtStBkReclnUpwdDnwdPos.Val
            PA_KeSMSw6sAcsEntryThdRwLtStBkReclnUpwdDnwdPosMax_Val: accessed-parameter=KeSMSw6sAcsEntryThdRwLtStBkReclnUpwdDnwdPosMax.Val
            PA_KeSMSw6sAcsEntryThdRwLtStBkReclnUpwdDnwdPosMin_Val: accessed-parameter=KeSMSw6sAcsEntryThdRwLtStBkReclnUpwdDnwdPosMin.Val
            PA_KeSMSw6sAcsEntryThdRwLtStCshnFldUpwdDnwdPos_Val: accessed-parameter=KeSMSw6sAcsEntryThdRwLtStCshnFldUpwdDnwdPos.Val
            PA_KeSMSw6sAcsEntryThdRwLtStCshnFldUpwdDnwdPosMax_Val: accessed-parameter=KeSMSw6sAcsEntryThdRwLtStCshnFldUpwdDnwdPosMax.Val
            PA_KeSMSw6sAcsEntryThdRwLtStCshnFldUpwdDnwdPosMin_Val: accessed-parameter=KeSMSw6sAcsEntryThdRwLtStCshnFldUpwdDnwdPosMin.Val
            PA_KeSMSw6sAcsEntryThdRwLtStFrwdBkwdPos_Val: accessed-parameter=KeSMSw6sAcsEntryThdRwLtStFrwdBkwdPos.Val
            PA_KeSMSw6sAcsEntryThdRwLtStFrwdBkwdPosMax_Val: accessed-parameter=KeSMSw6sAcsEntryThdRwLtStFrwdBkwdPosMax.Val
            PA_KeSMSw6sAcsEntryThdRwLtStFrwdBkwdPosMin_Val: accessed-parameter=KeSMSw6sAcsEntryThdRwLtStFrwdBkwdPosMin.Val
            PA_KeSMSw6SAcsMd56ThdRwLtStBkReclnUpwdDnwdPos_Val: accessed-parameter=KeSMSw6SAcsMd56ThdRwLtStBkReclnUpwdDnwdPos.Val
            PA_KeSMSw6SAcsMd56ThdRwLtStBkReclnUpwdDnwdPosMax_Val: accessed-parameter=KeSMSw6SAcsMd56ThdRwLtStBkReclnUpwdDnwdPosMax.Val
            PA_KeSMSw6SAcsMd56ThdRwLtStBkReclnUpwdDnwdPosMin_Val: accessed-parameter=KeSMSw6SAcsMd56ThdRwLtStBkReclnUpwdDnwdPosMin.Val
            PA_KeSMSw6SAcsMd56ThdRwLtStFrwdBkwdPos_Val: accessed-parameter=KeSMSw6SAcsMd56ThdRwLtStFrwdBkwdPos.Val
            PA_KeSMSw6SAcsMd56ThdRwLtStFrwdBkwdPosMax_Val: accessed-parameter=KeSMSw6SAcsMd56ThdRwLtStFrwdBkwdPosMax.Val
            PA_KeSMSw6SAcsMd56ThdRwLtStFrwdBkwdPosMin_Val: accessed-parameter=KeSMSw6SAcsMd56ThdRwLtStFrwdBkwdPosMin.Val
            PA_KeSMSw6sFamilyLMdThdRwLtStFrwdBkwdPos_Val: accessed-parameter=KeSMSw6sFamilyLMdThdRwLtStFrwdBkwdPos.Val
            PA_KeSMSw6sFamilyLMdThdRwLtStFrwdBkwdPosMax_Val: accessed-parameter=KeSMSw6sFamilyLMdThdRwLtStFrwdBkwdPosMax.Val
            PA_KeSMSw6sFamilyLMdThdRwLtStFrwdBkwdPosMin_Val: accessed-parameter=KeSMSw6sFamilyLMdThdRwLtStFrwdBkwdPosMin.Val
            PA_KeSMSw6sFamilyMdThdRwLtStFrwdBkwdPos_Val: accessed-parameter=KeSMSw6sFamilyMdThdRwLtStFrwdBkwdPos.Val
            PA_KeSMSw6sFamilyMdThdRwLtStFrwdBkwdPosMax_Val: accessed-parameter=KeSMSw6sFamilyMdThdRwLtStFrwdBkwdPosMax.Val
            PA_KeSMSw6sFamilyMdThdRwLtStFrwdBkwdPosMin_Val: accessed-parameter=KeSMSw6sFamilyMdThdRwLtStFrwdBkwdPosMin.Val
            PA_KeSMSw6sLugThdRwLtStBkReclnUpwdDnwdPos_Val: accessed-parameter=KeSMSw6sLugThdRwLtStBkReclnUpwdDnwdPos.Val
            PA_KeSMSw6sLugThdRwLtStBkReclnUpwdDnwdPosMax_Val: accessed-parameter=KeSMSw6sLugThdRwLtStBkReclnUpwdDnwdPosMax.Val
            PA_KeSMSw6sLugThdRwLtStBkReclnUpwdDnwdPosMin_Val: accessed-parameter=KeSMSw6sLugThdRwLtStBkReclnUpwdDnwdPosMin.Val
            PA_KeSMSw6sLugThdRwLtStCshnFldUpwdDnwdPos_Val: accessed-parameter=KeSMSw6sLugThdRwLtStCshnFldUpwdDnwdPos.Val
            PA_KeSMSw6sLugThdRwLtStCshnFldUpwdDnwdPosMax_Val: accessed-parameter=KeSMSw6sLugThdRwLtStCshnFldUpwdDnwdPosMax.Val
            PA_KeSMSw6sLugThdRwLtStCshnFldUpwdDnwdPosMin_Val: accessed-parameter=KeSMSw6sLugThdRwLtStCshnFldUpwdDnwdPosMin.Val
            PA_KeSMSw6sLugThdRwLtStFrwdBkwdPos_Val: accessed-parameter=KeSMSw6sLugThdRwLtStFrwdBkwdPos.Val
            PA_KeSMSw6sLugThdRwLtStFrwdBkwdPosMax_Val: accessed-parameter=KeSMSw6sLugThdRwLtStFrwdBkwdPosMax.Val
            PA_KeSMSw6sLugThdRwLtStFrwdBkwdPosMin_Val: accessed-parameter=KeSMSw6sLugThdRwLtStFrwdBkwdPosMin.Val
            PA_KeSMSw6sVIPThdRwLtStBkReclnUpwdDnwdPos_Val: accessed-parameter=KeSMSw6sVIPThdRwLtStBkReclnUpwdDnwdPos.Val
            PA_KeSMSw6sVIPThdRwLtStBkReclnUpwdDnwdPosMax_Val: accessed-parameter=KeSMSw6sVIPThdRwLtStBkReclnUpwdDnwdPosMax.Val
            PA_KeSMSw6sVIPThdRwLtStBkReclnUpwdDnwdPosMin_Val: accessed-parameter=KeSMSw6sVIPThdRwLtStBkReclnUpwdDnwdPosMin.Val
            PA_KeSMSw6sVIPThdRwLtStFrwdBkwdPos_Val: accessed-parameter=KeSMSw6sVIPThdRwLtStFrwdBkwdPos.Val
            PA_KeSMSw6sVIPThdRwLtStFrwdBkwdPosMax_Val: accessed-parameter=KeSMSw6sVIPThdRwLtStFrwdBkwdPosMax.Val
            PA_KeSMSw6sVIPThdRwLtStFrwdBkwdPosMin_Val: accessed-parameter=KeSMSw6sVIPThdRwLtStFrwdBkwdPosMin.Val
            PA_KeSMSwAcsEntryThdRwLtStBkReclnUpwdDnwdPos_Val: accessed-parameter=KeSMSwAcsEntryThdRwLtStBkReclnUpwdDnwdPos.Val
            PA_KeSMSwAcsEntryThdRwLtStBkReclnUpwdDnwdPosMax_Val: accessed-parameter=KeSMSwAcsEntryThdRwLtStBkReclnUpwdDnwdPosMax.Val
            PA_KeSMSwAcsEntryThdRwLtStBkReclnUpwdDnwdPosMin_Val: accessed-parameter=KeSMSwAcsEntryThdRwLtStBkReclnUpwdDnwdPosMin.Val
            PA_KeSMSwAcsEntryThdRwLtStCshnFldUpwdDnwdPos_Val: accessed-parameter=KeSMSwAcsEntryThdRwLtStCshnFldUpwdDnwdPos.Val
            PA_KeSMSwAcsEntryThdRwLtStCshnFldUpwdDnwdPosMax_Val: accessed-parameter=KeSMSwAcsEntryThdRwLtStCshnFldUpwdDnwdPosMax.Val
            PA_KeSMSwAcsEntryThdRwLtStCshnFldUpwdDnwdPosMin_Val: accessed-parameter=KeSMSwAcsEntryThdRwLtStCshnFldUpwdDnwdPosMin.Val
            PA_KeSMSwAcsEntryThdRwLtStFrwdBkwdPos_Val: accessed-parameter=KeSMSwAcsEntryThdRwLtStFrwdBkwdPos.Val
            PA_KeSMSwAcsEntryThdRwLtStFrwdBkwdPosMax_Val: accessed-parameter=KeSMSwAcsEntryThdRwLtStFrwdBkwdPosMax.Val
            PA_KeSMSwAcsEntryThdRwLtStFrwdBkwdPosMin_Val: accessed-parameter=KeSMSwAcsEntryThdRwLtStFrwdBkwdPosMin.Val
            PA_KeSMSwAcsMd32ThdRwLtBkReclnUpwdDnwdPos_Val: accessed-parameter=KeSMSwAcsMd32ThdRwLtBkReclnUpwdDnwdPos.Val
            PA_KeSMSwAcsMd32ThdRwLtBkReclnUpwdDnwdPosMax_Val: accessed-parameter=KeSMSwAcsMd32ThdRwLtBkReclnUpwdDnwdPosMax.Val
            PA_KeSMSwAcsMd32ThdRwLtBkReclnUpwdDnwdPosMin_Val: accessed-parameter=KeSMSwAcsMd32ThdRwLtBkReclnUpwdDnwdPosMin.Val
            PA_KeSMSwAcsMd32ThdRwLtFldUpwdDnwdPos_Val: accessed-parameter=KeSMSwAcsMd32ThdRwLtFldUpwdDnwdPos.Val
            PA_KeSMSwAcsMd32ThdRwLtFldUpwdDnwdPosMax_Val: accessed-parameter=KeSMSwAcsMd32ThdRwLtFldUpwdDnwdPosMax.Val
            PA_KeSMSwAcsMd32ThdRwLtFldUpwdDnwdPosMin_Val: accessed-parameter=KeSMSwAcsMd32ThdRwLtFldUpwdDnwdPosMin.Val
            PA_KeSMSwAcsMd56ThdRwLtStBkReclnUpwdDnwdPos_Val: accessed-parameter=KeSMSwAcsMd56ThdRwLtStBkReclnUpwdDnwdPos.Val
            PA_KeSMSwAcsMd56ThdRwLtStBkReclnUpwdDnwdPosMax_Val: accessed-parameter=KeSMSwAcsMd56ThdRwLtStBkReclnUpwdDnwdPosMax.Val
            PA_KeSMSwAcsMd56ThdRwLtStBkReclnUpwdDnwdPosMin_Val: accessed-parameter=KeSMSwAcsMd56ThdRwLtStBkReclnUpwdDnwdPosMin.Val
            PA_KeSMSwAcsMd56ThdRwLtStCshnFldUpwdDnwdPos_Val: accessed-parameter=KeSMSwAcsMd56ThdRwLtStCshnFldUpwdDnwdPos.Val
            PA_KeSMSwAcsMd56ThdRwLtStCshnFldUpwdDnwdPosMax_Val: accessed-parameter=KeSMSwAcsMd56ThdRwLtStCshnFldUpwdDnwdPosMax.Val
            PA_KeSMSwAcsMd56ThdRwLtStCshnFldUpwdDnwdPosMin_Val: accessed-parameter=KeSMSwAcsMd56ThdRwLtStCshnFldUpwdDnwdPosMin.Val
            PA_KeSMSwAcsMd56ThdRwLtStFrwdBkwdPos_Val: accessed-parameter=KeSMSwAcsMd56ThdRwLtStFrwdBkwdPos.Val
            PA_KeSMSwAcsMd56ThdRwLtStFrwdBkwdPosMax_Val: accessed-parameter=KeSMSwAcsMd56ThdRwLtStFrwdBkwdPosMax.Val
            PA_KeSMSwAcsMd56ThdRwLtStFrwdBkwdPosMin_Val: accessed-parameter=KeSMSwAcsMd56ThdRwLtStFrwdBkwdPosMin.Val
            PA_KeSMSwAcsMd57ThdRwLtStBkReclnUpwdDnwdPos_Val: accessed-parameter=KeSMSwAcsMd57ThdRwLtStBkReclnUpwdDnwdPos.Val
            PA_KeSMSwAcsMd57ThdRwLtStBkReclnUpwdDnwdPosMax_Val: accessed-parameter=KeSMSwAcsMd57ThdRwLtStBkReclnUpwdDnwdPosMax.Val
            PA_KeSMSwAcsMd57ThdRwLtStBkReclnUpwdDnwdPosMin_Val: accessed-parameter=KeSMSwAcsMd57ThdRwLtStBkReclnUpwdDnwdPosMin.Val
            PA_KeSMSwAcsMd57ThdRwLtStFrwdBkwdPos_Val: accessed-parameter=KeSMSwAcsMd57ThdRwLtStFrwdBkwdPos.Val
            PA_KeSMSwAcsMd57ThdRwLtStFrwdBkwdPosMax_Val: accessed-parameter=KeSMSwAcsMd57ThdRwLtStFrwdBkwdPosMax.Val
            PA_KeSMSwAcsMd57ThdRwLtStFrwdBkwdPosMin_Val: accessed-parameter=KeSMSwAcsMd57ThdRwLtStFrwdBkwdPosMin.Val
            PA_KeSMSwAcsMd6ThdRwLtStBkReclnUpwdDnwdPos_Val: accessed-parameter=KeSMSwAcsMd6ThdRwLtStBkReclnUpwdDnwdPos.Val
            PA_KeSMSwAcsMd6ThdRwLtStBkReclnUpwdDnwdPosMax_Val: accessed-parameter=KeSMSwAcsMd6ThdRwLtStBkReclnUpwdDnwdPosMax.Val
            PA_KeSMSwAcsMd6ThdRwLtStBkReclnUpwdDnwdPosMin_Val: accessed-parameter=KeSMSwAcsMd6ThdRwLtStBkReclnUpwdDnwdPosMin.Val
            PA_KeSMSwAcsMd6ThdRwLtStCshnFldUpwdDnwdPos_Val: accessed-parameter=KeSMSwAcsMd6ThdRwLtStCshnFldUpwdDnwdPos.Val
            PA_KeSMSwAcsMd6ThdRwLtStCshnFldUpwdDnwdPosMax_Val: accessed-parameter=KeSMSwAcsMd6ThdRwLtStCshnFldUpwdDnwdPosMax.Val
            PA_KeSMSwAcsMd6ThdRwLtStCshnFldUpwdDnwdPosMin_Val: accessed-parameter=KeSMSwAcsMd6ThdRwLtStCshnFldUpwdDnwdPosMin.Val
            PA_KeSMSwAcsMd6ThdRwLtStFrwdBkwdPos_Val: accessed-parameter=KeSMSwAcsMd6ThdRwLtStFrwdBkwdPos.Val
            PA_KeSMSwAcsMd6ThdRwLtStFrwdBkwdPosMax_Val: accessed-parameter=KeSMSwAcsMd6ThdRwLtStFrwdBkwdPosMax.Val
            PA_KeSMSwAcsMd6ThdRwLtStFrwdBkwdPosMin_Val: accessed-parameter=KeSMSwAcsMd6ThdRwLtStFrwdBkwdPosMin.Val
            PA_KeSMSwFamilyLMdThdRwLtStFrwdBkwdPos_Val: accessed-parameter=KeSMSwFamilyLMdThdRwLtStFrwdBkwdPos.Val
            PA_KeSMSwFamilyLMdThdRwLtStFrwdBkwdPosMax_Val: accessed-parameter=KeSMSwFamilyLMdThdRwLtStFrwdBkwdPosMax.Val
            PA_KeSMSwFamilyLMdThdRwLtStFrwdBkwdPosMin_Val: accessed-parameter=KeSMSwFamilyLMdThdRwLtStFrwdBkwdPosMin.Val
            PA_KeSMSwFamilyMdThdRwLtStFrwdBkwdPos_Val: accessed-parameter=KeSMSwFamilyMdThdRwLtStFrwdBkwdPos.Val
            PA_KeSMSwFamilyMdThdRwLtStFrwdBkwdPosMax_Val: accessed-parameter=KeSMSwFamilyMdThdRwLtStFrwdBkwdPosMax.Val
            PA_KeSMSwFamilyMdThdRwLtStFrwdBkwdPosMin_Val: accessed-parameter=KeSMSwFamilyMdThdRwLtStFrwdBkwdPosMin.Val
            PA_KeSMSwLugThdRwLtStBkReclnUpwdDnwdPos_Val: accessed-parameter=KeSMSwLugThdRwLtStBkReclnUpwdDnwdPos.Val
            PA_KeSMSwLugThdRwLtStBkReclnUpwdDnwdPosMax_Val: accessed-parameter=KeSMSwLugThdRwLtStBkReclnUpwdDnwdPosMax.Val
            PA_KeSMSwLugThdRwLtStBkReclnUpwdDnwdPosMin_Val: accessed-parameter=KeSMSwLugThdRwLtStBkReclnUpwdDnwdPosMin.Val
            PA_KeSMSwLugThdRwLtStCshnFldUpwdDnwdPos_Val: accessed-parameter=KeSMSwLugThdRwLtStCshnFldUpwdDnwdPos.Val
            PA_KeSMSwLugThdRwLtStCshnFldUpwdDnwdPosMax_Val: accessed-parameter=KeSMSwLugThdRwLtStCshnFldUpwdDnwdPosMax.Val
            PA_KeSMSwLugThdRwLtStCshnFldUpwdDnwdPosMin_Val: accessed-parameter=KeSMSwLugThdRwLtStCshnFldUpwdDnwdPosMin.Val
            PA_KeSMSwLugThdRwLtStFrwdBkwdPos_Val: accessed-parameter=KeSMSwLugThdRwLtStFrwdBkwdPos.Val
            PA_KeSMSwLugThdRwLtStFrwdBkwdPosMax_Val: accessed-parameter=KeSMSwLugThdRwLtStFrwdBkwdPosMax.Val
            PA_KeSMSwLugThdRwLtStFrwdBkwdPosMin_Val: accessed-parameter=KeSMSwLugThdRwLtStFrwdBkwdPosMin.Val
            PA_KeSMSwThdRwLtStBkReclnEnTrigBitMask_Val: accessed-parameter=KeSMSwThdRwLtStBkReclnEnTrigBitMask.Val
            PA_KeSMSwThdRwLtStBkReclnEnTrigBitMask6s_Val: accessed-parameter=KeSMSwThdRwLtStBkReclnEnTrigBitMask6s.Val
            PA_KeSMSwThdRwLtStFwdBkwdEnTrigBitMask_Val: accessed-parameter=KeSMSwThdRwLtStFwdBkwdEnTrigBitMask.Val
            PA_KeSMSwThdRwLtStFwdBkwdEnTrigBitMask6s_Val: accessed-parameter=KeSMSwThdRwLtStFwdBkwdEnTrigBitMask6s.Val
            PA_KeSMSwVIPThdRwLtStBkReclnUpwdDnwdPos_Val: accessed-parameter=KeSMSwVIPThdRwLtStBkReclnUpwdDnwdPos.Val
            PA_KeSMSwVIPThdRwLtStBkReclnUpwdDnwdPosMax_Val: accessed-parameter=KeSMSwVIPThdRwLtStBkReclnUpwdDnwdPosMax.Val
            PA_KeSMSwVIPThdRwLtStBkReclnUpwdDnwdPosMin_Val: accessed-parameter=KeSMSwVIPThdRwLtStBkReclnUpwdDnwdPosMin.Val
            PA_KeSMSwVIPThdRwLtStFrwdBkwdPos_Val: accessed-parameter=KeSMSwVIPThdRwLtStFrwdBkwdPos.Val
            PA_KeSMSwVIPThdRwLtStFrwdBkwdPosMax_Val: accessed-parameter=KeSMSwVIPThdRwLtStFrwdBkwdPosMax.Val
            PA_KeSMSwVIPThdRwLtStFrwdBkwdPosMin_Val: accessed-parameter=KeSMSwVIPThdRwLtStFrwdBkwdPosMin.Val
        ThdRwLtStCshnFldTrgtPosSelc_1_Cal
          data-receive-point-by-arguments:
            4 x access:
              REC_StNumFlg_Is4s: accessed-variable=StNumFlg.Is4s
              REC_StNumFlg_Is6s: accessed-variable=StNumFlg.Is6s
              REC_StNumFlg_Is6s7s: accessed-variable=StNumFlg.Is6s7s
              REC_StNumFlg_Is7s: accessed-variable=StNumFlg.Is7s
          data-send-points:
            5 x access:
              SEND_EZER3LCshnFldTrgtPosCalib_TrgtPosArray: accessed-variable=EZER3LCshnFldTrgtPosCalib.TrgtPosArray
              SEND_LugLR3LCshnFldTrgtPosCalib_TrgtPosArray: accessed-variable=LugLR3LCshnFldTrgtPosCalib.TrgtPosArray
              SEND_Md27R3LCshnFldTrgtPosCalib_TrgtPosArray: accessed-variable=Md27R3LCshnFldTrgtPosCalib.TrgtPosArray
              SEND_Md32CshnFldTrgtPosCalib_TrgtPosArray: accessed-variable=Md32CshnFldTrgtPosCalib.TrgtPosArray
              SEND_Md56R3LCshnFldTrgtPosCalib_TrgtPosArray: accessed-variable=Md56R3LCshnFldTrgtPosCalib.TrgtPosArray
          100 x parameter access:
            PA_KeSMSw6sAcsEntryThdRwLtStBkReclnUpwdDnwdPos_Val: accessed-parameter=KeSMSw6sAcsEntryThdRwLtStBkReclnUpwdDnwdPos.Val
            PA_KeSMSw6sAcsEntryThdRwLtStBkReclnUpwdDnwdPosMax_Val: accessed-parameter=KeSMSw6sAcsEntryThdRwLtStBkReclnUpwdDnwdPosMax.Val
            PA_KeSMSw6sAcsEntryThdRwLtStBkReclnUpwdDnwdPosMin_Val: accessed-parameter=KeSMSw6sAcsEntryThdRwLtStBkReclnUpwdDnwdPosMin.Val
            PA_KeSMSw6sAcsEntryThdRwLtStCshnFldUpwdDnwdPos_Val: accessed-parameter=KeSMSw6sAcsEntryThdRwLtStCshnFldUpwdDnwdPos.Val
            PA_KeSMSw6sAcsEntryThdRwLtStCshnFldUpwdDnwdPosMax_Val: accessed-parameter=KeSMSw6sAcsEntryThdRwLtStCshnFldUpwdDnwdPosMax.Val
            PA_KeSMSw6sAcsEntryThdRwLtStCshnFldUpwdDnwdPosMin_Val: accessed-parameter=KeSMSw6sAcsEntryThdRwLtStCshnFldUpwdDnwdPosMin.Val
            PA_KeSMSw6sAcsEntryThdRwLtStFrwdBkwdPos_Val: accessed-parameter=KeSMSw6sAcsEntryThdRwLtStFrwdBkwdPos.Val
            PA_KeSMSw6sAcsEntryThdRwLtStFrwdBkwdPosMax_Val: accessed-parameter=KeSMSw6sAcsEntryThdRwLtStFrwdBkwdPosMax.Val
            PA_KeSMSw6sAcsEntryThdRwLtStFrwdBkwdPosMin_Val: accessed-parameter=KeSMSw6sAcsEntryThdRwLtStFrwdBkwdPosMin.Val
            PA_KeSMSw6SAcsMd56ThdRwLtStBkReclnUpwdDnwdPos_Val: accessed-parameter=KeSMSw6SAcsMd56ThdRwLtStBkReclnUpwdDnwdPos.Val
            PA_KeSMSw6SAcsMd56ThdRwLtStBkReclnUpwdDnwdPosMax_Val: accessed-parameter=KeSMSw6SAcsMd56ThdRwLtStBkReclnUpwdDnwdPosMax.Val
            PA_KeSMSw6SAcsMd56ThdRwLtStBkReclnUpwdDnwdPosMin_Val: accessed-parameter=KeSMSw6SAcsMd56ThdRwLtStBkReclnUpwdDnwdPosMin.Val
            PA_KeSMSw6SAcsMd56ThdRwLtStFrwdBkwdPos_Val: accessed-parameter=KeSMSw6SAcsMd56ThdRwLtStFrwdBkwdPos.Val
            PA_KeSMSw6SAcsMd56ThdRwLtStFrwdBkwdPosMax_Val: accessed-parameter=KeSMSw6SAcsMd56ThdRwLtStFrwdBkwdPosMax.Val
            PA_KeSMSw6SAcsMd56ThdRwLtStFrwdBkwdPosMin_Val: accessed-parameter=KeSMSw6SAcsMd56ThdRwLtStFrwdBkwdPosMin.Val
            PA_KeSMSw6sFamilyLMdThdRwLtStFrwdBkwdPos_Val: accessed-parameter=KeSMSw6sFamilyLMdThdRwLtStFrwdBkwdPos.Val
            PA_KeSMSw6sFamilyLMdThdRwLtStFrwdBkwdPosMax_Val: accessed-parameter=KeSMSw6sFamilyLMdThdRwLtStFrwdBkwdPosMax.Val
            PA_KeSMSw6sFamilyLMdThdRwLtStFrwdBkwdPosMin_Val: accessed-parameter=KeSMSw6sFamilyLMdThdRwLtStFrwdBkwdPosMin.Val
            PA_KeSMSw6sFamilyMdThdRwLtStFrwdBkwdPos_Val: accessed-parameter=KeSMSw6sFamilyMdThdRwLtStFrwdBkwdPos.Val
            PA_KeSMSw6sFamilyMdThdRwLtStFrwdBkwdPosMax_Val: accessed-parameter=KeSMSw6sFamilyMdThdRwLtStFrwdBkwdPosMax.Val
            PA_KeSMSw6sFamilyMdThdRwLtStFrwdBkwdPosMin_Val: accessed-parameter=KeSMSw6sFamilyMdThdRwLtStFrwdBkwdPosMin.Val
            PA_KeSMSw6sLugThdRwLtStBkReclnUpwdDnwdPos_Val: accessed-parameter=KeSMSw6sLugThdRwLtStBkReclnUpwdDnwdPos.Val
            PA_KeSMSw6sLugThdRwLtStBkReclnUpwdDnwdPosMax_Val: accessed-parameter=KeSMSw6sLugThdRwLtStBkReclnUpwdDnwdPosMax.Val
            PA_KeSMSw6sLugThdRwLtStBkReclnUpwdDnwdPosMin_Val: accessed-parameter=KeSMSw6sLugThdRwLtStBkReclnUpwdDnwdPosMin.Val
            PA_KeSMSw6sLugThdRwLtStCshnFldUpwdDnwdPos_Val: accessed-parameter=KeSMSw6sLugThdRwLtStCshnFldUpwdDnwdPos.Val
            PA_KeSMSw6sLugThdRwLtStCshnFldUpwdDnwdPosMax_Val: accessed-parameter=KeSMSw6sLugThdRwLtStCshnFldUpwdDnwdPosMax.Val
            PA_KeSMSw6sLugThdRwLtStCshnFldUpwdDnwdPosMin_Val: accessed-parameter=KeSMSw6sLugThdRwLtStCshnFldUpwdDnwdPosMin.Val
            PA_KeSMSw6sLugThdRwLtStFrwdBkwdPos_Val: accessed-parameter=KeSMSw6sLugThdRwLtStFrwdBkwdPos.Val
            PA_KeSMSw6sLugThdRwLtStFrwdBkwdPosMax_Val: accessed-parameter=KeSMSw6sLugThdRwLtStFrwdBkwdPosMax.Val
            PA_KeSMSw6sLugThdRwLtStFrwdBkwdPosMin_Val: accessed-parameter=KeSMSw6sLugThdRwLtStFrwdBkwdPosMin.Val
            PA_KeSMSw6sVIPThdRwLtStBkReclnUpwdDnwdPos_Val: accessed-parameter=KeSMSw6sVIPThdRwLtStBkReclnUpwdDnwdPos.Val
            PA_KeSMSw6sVIPThdRwLtStBkReclnUpwdDnwdPosMax_Val: accessed-parameter=KeSMSw6sVIPThdRwLtStBkReclnUpwdDnwdPosMax.Val
            PA_KeSMSw6sVIPThdRwLtStBkReclnUpwdDnwdPosMin_Val: accessed-parameter=KeSMSw6sVIPThdRwLtStBkReclnUpwdDnwdPosMin.Val
            PA_KeSMSw6sVIPThdRwLtStFrwdBkwdPos_Val: accessed-parameter=KeSMSw6sVIPThdRwLtStFrwdBkwdPos.Val
            PA_KeSMSw6sVIPThdRwLtStFrwdBkwdPosMax_Val: accessed-parameter=KeSMSw6sVIPThdRwLtStFrwdBkwdPosMax.Val
            PA_KeSMSw6sVIPThdRwLtStFrwdBkwdPosMin_Val: accessed-parameter=KeSMSw6sVIPThdRwLtStFrwdBkwdPosMin.Val
            PA_KeSMSwAcsEntryThdRwLtStBkReclnUpwdDnwdPos_Val: accessed-parameter=KeSMSwAcsEntryThdRwLtStBkReclnUpwdDnwdPos.Val
            PA_KeSMSwAcsEntryThdRwLtStBkReclnUpwdDnwdPosMax_Val: accessed-parameter=KeSMSwAcsEntryThdRwLtStBkReclnUpwdDnwdPosMax.Val
            PA_KeSMSwAcsEntryThdRwLtStBkReclnUpwdDnwdPosMin_Val: accessed-parameter=KeSMSwAcsEntryThdRwLtStBkReclnUpwdDnwdPosMin.Val
            PA_KeSMSwAcsEntryThdRwLtStCshnFldUpwdDnwdPos_Val: accessed-parameter=KeSMSwAcsEntryThdRwLtStCshnFldUpwdDnwdPos.Val
            PA_KeSMSwAcsEntryThdRwLtStCshnFldUpwdDnwdPosMax_Val: accessed-parameter=KeSMSwAcsEntryThdRwLtStCshnFldUpwdDnwdPosMax.Val
            PA_KeSMSwAcsEntryThdRwLtStCshnFldUpwdDnwdPosMin_Val: accessed-parameter=KeSMSwAcsEntryThdRwLtStCshnFldUpwdDnwdPosMin.Val
            PA_KeSMSwAcsEntryThdRwLtStFrwdBkwdPos_Val: accessed-parameter=KeSMSwAcsEntryThdRwLtStFrwdBkwdPos.Val
            PA_KeSMSwAcsEntryThdRwLtStFrwdBkwdPosMax_Val: accessed-parameter=KeSMSwAcsEntryThdRwLtStFrwdBkwdPosMax.Val
            PA_KeSMSwAcsEntryThdRwLtStFrwdBkwdPosMin_Val: accessed-parameter=KeSMSwAcsEntryThdRwLtStFrwdBkwdPosMin.Val
            PA_KeSMSwAcsMd32ThdRwLtBkReclnUpwdDnwdPos_Val: accessed-parameter=KeSMSwAcsMd32ThdRwLtBkReclnUpwdDnwdPos.Val
            PA_KeSMSwAcsMd32ThdRwLtBkReclnUpwdDnwdPosMax_Val: accessed-parameter=KeSMSwAcsMd32ThdRwLtBkReclnUpwdDnwdPosMax.Val
            PA_KeSMSwAcsMd32ThdRwLtBkReclnUpwdDnwdPosMin_Val: accessed-parameter=KeSMSwAcsMd32ThdRwLtBkReclnUpwdDnwdPosMin.Val
            PA_KeSMSwAcsMd32ThdRwLtFldUpwdDnwdPos_Val: accessed-parameter=KeSMSwAcsMd32ThdRwLtFldUpwdDnwdPos.Val
            PA_KeSMSwAcsMd32ThdRwLtFldUpwdDnwdPosMax_Val: accessed-parameter=KeSMSwAcsMd32ThdRwLtFldUpwdDnwdPosMax.Val
            PA_KeSMSwAcsMd32ThdRwLtFldUpwdDnwdPosMin_Val: accessed-parameter=KeSMSwAcsMd32ThdRwLtFldUpwdDnwdPosMin.Val
            PA_KeSMSwAcsMd56ThdRwLtStBkReclnUpwdDnwdPos_Val: accessed-parameter=KeSMSwAcsMd56ThdRwLtStBkReclnUpwdDnwdPos.Val
            PA_KeSMSwAcsMd56ThdRwLtStBkReclnUpwdDnwdPosMax_Val: accessed-parameter=KeSMSwAcsMd56ThdRwLtStBkReclnUpwdDnwdPosMax.Val
            PA_KeSMSwAcsMd56ThdRwLtStBkReclnUpwdDnwdPosMin_Val: accessed-parameter=KeSMSwAcsMd56ThdRwLtStBkReclnUpwdDnwdPosMin.Val
            PA_KeSMSwAcsMd56ThdRwLtStCshnFldUpwdDnwdPos_Val: accessed-parameter=KeSMSwAcsMd56ThdRwLtStCshnFldUpwdDnwdPos.Val
            PA_KeSMSwAcsMd56ThdRwLtStCshnFldUpwdDnwdPosMax_Val: accessed-parameter=KeSMSwAcsMd56ThdRwLtStCshnFldUpwdDnwdPosMax.Val
            PA_KeSMSwAcsMd56ThdRwLtStCshnFldUpwdDnwdPosMin_Val: accessed-parameter=KeSMSwAcsMd56ThdRwLtStCshnFldUpwdDnwdPosMin.Val
            PA_KeSMSwAcsMd56ThdRwLtStFrwdBkwdPos_Val: accessed-parameter=KeSMSwAcsMd56ThdRwLtStFrwdBkwdPos.Val
            PA_KeSMSwAcsMd56ThdRwLtStFrwdBkwdPosMax_Val: accessed-parameter=KeSMSwAcsMd56ThdRwLtStFrwdBkwdPosMax.Val
            PA_KeSMSwAcsMd56ThdRwLtStFrwdBkwdPosMin_Val: accessed-parameter=KeSMSwAcsMd56ThdRwLtStFrwdBkwdPosMin.Val
            PA_KeSMSwAcsMd57ThdRwLtStBkReclnUpwdDnwdPos_Val: accessed-parameter=KeSMSwAcsMd57ThdRwLtStBkReclnUpwdDnwdPos.Val
            PA_KeSMSwAcsMd57ThdRwLtStBkReclnUpwdDnwdPosMax_Val: accessed-parameter=KeSMSwAcsMd57ThdRwLtStBkReclnUpwdDnwdPosMax.Val
            PA_KeSMSwAcsMd57ThdRwLtStBkReclnUpwdDnwdPosMin_Val: accessed-parameter=KeSMSwAcsMd57ThdRwLtStBkReclnUpwdDnwdPosMin.Val
            PA_KeSMSwAcsMd57ThdRwLtStFrwdBkwdPos_Val: accessed-parameter=KeSMSwAcsMd57ThdRwLtStFrwdBkwdPos.Val
            PA_KeSMSwAcsMd57ThdRwLtStFrwdBkwdPosMax_Val: accessed-parameter=KeSMSwAcsMd57ThdRwLtStFrwdBkwdPosMax.Val
            PA_KeSMSwAcsMd57ThdRwLtStFrwdBkwdPosMin_Val: accessed-parameter=KeSMSwAcsMd57ThdRwLtStFrwdBkwdPosMin.Val
            PA_KeSMSwAcsMd6ThdRwLtStBkReclnUpwdDnwdPos_Val: accessed-parameter=KeSMSwAcsMd6ThdRwLtStBkReclnUpwdDnwdPos.Val
            PA_KeSMSwAcsMd6ThdRwLtStBkReclnUpwdDnwdPosMax_Val: accessed-parameter=KeSMSwAcsMd6ThdRwLtStBkReclnUpwdDnwdPosMax.Val
            PA_KeSMSwAcsMd6ThdRwLtStBkReclnUpwdDnwdPosMin_Val: accessed-parameter=KeSMSwAcsMd6ThdRwLtStBkReclnUpwdDnwdPosMin.Val
            PA_KeSMSwAcsMd6ThdRwLtStCshnFldUpwdDnwdPos_Val: accessed-parameter=KeSMSwAcsMd6ThdRwLtStCshnFldUpwdDnwdPos.Val
            PA_KeSMSwAcsMd6ThdRwLtStCshnFldUpwdDnwdPosMax_Val: accessed-parameter=KeSMSwAcsMd6ThdRwLtStCshnFldUpwdDnwdPosMax.Val
            PA_KeSMSwAcsMd6ThdRwLtStCshnFldUpwdDnwdPosMin_Val: accessed-parameter=KeSMSwAcsMd6ThdRwLtStCshnFldUpwdDnwdPosMin.Val
            PA_KeSMSwAcsMd6ThdRwLtStFrwdBkwdPos_Val: accessed-parameter=KeSMSwAcsMd6ThdRwLtStFrwdBkwdPos.Val
            PA_KeSMSwAcsMd6ThdRwLtStFrwdBkwdPosMax_Val: accessed-parameter=KeSMSwAcsMd6ThdRwLtStFrwdBkwdPosMax.Val
            PA_KeSMSwAcsMd6ThdRwLtStFrwdBkwdPosMin_Val: accessed-parameter=KeSMSwAcsMd6ThdRwLtStFrwdBkwdPosMin.Val
            PA_KeSMSwFamilyLMdThdRwLtStFrwdBkwdPos_Val: accessed-parameter=KeSMSwFamilyLMdThdRwLtStFrwdBkwdPos.Val
            PA_KeSMSwFamilyLMdThdRwLtStFrwdBkwdPosMax_Val: accessed-parameter=KeSMSwFamilyLMdThdRwLtStFrwdBkwdPosMax.Val
            PA_KeSMSwFamilyLMdThdRwLtStFrwdBkwdPosMin_Val: accessed-parameter=KeSMSwFamilyLMdThdRwLtStFrwdBkwdPosMin.Val
            PA_KeSMSwFamilyMdThdRwLtStFrwdBkwdPos_Val: accessed-parameter=KeSMSwFamilyMdThdRwLtStFrwdBkwdPos.Val
            PA_KeSMSwFamilyMdThdRwLtStFrwdBkwdPosMax_Val: accessed-parameter=KeSMSwFamilyMdThdRwLtStFrwdBkwdPosMax.Val
            PA_KeSMSwFamilyMdThdRwLtStFrwdBkwdPosMin_Val: accessed-parameter=KeSMSwFamilyMdThdRwLtStFrwdBkwdPosMin.Val
            PA_KeSMSwLugThdRwLtStBkReclnUpwdDnwdPos_Val: accessed-parameter=KeSMSwLugThdRwLtStBkReclnUpwdDnwdPos.Val
            PA_KeSMSwLugThdRwLtStBkReclnUpwdDnwdPosMax_Val: accessed-parameter=KeSMSwLugThdRwLtStBkReclnUpwdDnwdPosMax.Val
            PA_KeSMSwLugThdRwLtStBkReclnUpwdDnwdPosMin_Val: accessed-parameter=KeSMSwLugThdRwLtStBkReclnUpwdDnwdPosMin.Val
            PA_KeSMSwLugThdRwLtStCshnFldUpwdDnwdPos_Val: accessed-parameter=KeSMSwLugThdRwLtStCshnFldUpwdDnwdPos.Val
            PA_KeSMSwLugThdRwLtStCshnFldUpwdDnwdPosMax_Val: accessed-parameter=KeSMSwLugThdRwLtStCshnFldUpwdDnwdPosMax.Val
            PA_KeSMSwLugThdRwLtStCshnFldUpwdDnwdPosMin_Val: accessed-parameter=KeSMSwLugThdRwLtStCshnFldUpwdDnwdPosMin.Val
            PA_KeSMSwLugThdRwLtStFrwdBkwdPos_Val: accessed-parameter=KeSMSwLugThdRwLtStFrwdBkwdPos.Val
            PA_KeSMSwLugThdRwLtStFrwdBkwdPosMax_Val: accessed-parameter=KeSMSwLugThdRwLtStFrwdBkwdPosMax.Val
            PA_KeSMSwLugThdRwLtStFrwdBkwdPosMin_Val: accessed-parameter=KeSMSwLugThdRwLtStFrwdBkwdPosMin.Val
            PA_KeSMSwThdRwLtStBkReclnEnTrigBitMask_Val: accessed-parameter=KeSMSwThdRwLtStBkReclnEnTrigBitMask.Val
            PA_KeSMSwThdRwLtStBkReclnEnTrigBitMask6s_Val: accessed-parameter=KeSMSwThdRwLtStBkReclnEnTrigBitMask6s.Val
            PA_KeSMSwThdRwLtStFwdBkwdEnTrigBitMask_Val: accessed-parameter=KeSMSwThdRwLtStFwdBkwdEnTrigBitMask.Val
            PA_KeSMSwThdRwLtStFwdBkwdEnTrigBitMask6s_Val: accessed-parameter=KeSMSwThdRwLtStFwdBkwdEnTrigBitMask6s.Val
            PA_KeSMSwVIPThdRwLtStBkReclnUpwdDnwdPos_Val: accessed-parameter=KeSMSwVIPThdRwLtStBkReclnUpwdDnwdPos.Val
            PA_KeSMSwVIPThdRwLtStBkReclnUpwdDnwdPosMax_Val: accessed-parameter=KeSMSwVIPThdRwLtStBkReclnUpwdDnwdPosMax.Val
            PA_KeSMSwVIPThdRwLtStBkReclnUpwdDnwdPosMin_Val: accessed-parameter=KeSMSwVIPThdRwLtStBkReclnUpwdDnwdPosMin.Val
            PA_KeSMSwVIPThdRwLtStFrwdBkwdPos_Val: accessed-parameter=KeSMSwVIPThdRwLtStFrwdBkwdPos.Val
            PA_KeSMSwVIPThdRwLtStFrwdBkwdPosMax_Val: accessed-parameter=KeSMSwVIPThdRwLtStFrwdBkwdPosMax.Val
            PA_KeSMSwVIPThdRwLtStFrwdBkwdPosMin_Val: accessed-parameter=KeSMSwVIPThdRwLtStFrwdBkwdPosMin.Val
        ThdRwLtStFwdBkwdTrgtPosSelc_1_Cal
          data-receive-point-by-arguments:
            5 x access:
              REC_IfVeSMSuThdRwLtStCshnFldUpwdDnwdPos_Val: accessed-variable=IfVeSMSuThdRwLtStCshnFldUpwdDnwdPos.Val
              REC_StNumFlg_Is4s: accessed-variable=StNumFlg.Is4s
              REC_StNumFlg_Is6s: accessed-variable=StNumFlg.Is6s
              REC_StNumFlg_Is6s7s: accessed-variable=StNumFlg.Is6s7s
              REC_StNumFlg_Is7s: accessed-variable=StNumFlg.Is7s
          data-send-points:
            9 x access:
              SEND_EZER3LFwdBkwdTrgtPosCalib_TrgtPosArray: accessed-variable=EZER3LFwdBkwdTrgtPosCalib.TrgtPosArray
              SEND_FAMLYLR3LFwdBkwdTrgtPosCalib_TrgtPosArray: accessed-variable=FAMLYLR3LFwdBkwdTrgtPosCalib.TrgtPosArray
              SEND_FAMLYRR3LFwdBkwdTrgtPosCalib_TrgtPosArray: accessed-variable=FAMLYRR3LFwdBkwdTrgtPosCalib.TrgtPosArray
              SEND_LugLR3LFwdBkwdTrgtPosCalib_TrgtPosArray: accessed-variable=LugLR3LFwdBkwdTrgtPosCalib.TrgtPosArray
              SEND_Md27R3LFwdBkwdTrgtPosCalib_TrgtPosArray: accessed-variable=Md27R3LFwdBkwdTrgtPosCalib.TrgtPosArray
              SEND_Md56R3LFwdBkwdTrgtPosCalib_TrgtPosArray: accessed-variable=Md56R3LFwdBkwdTrgtPosCalib.TrgtPosArray
              SEND_Md57R3LFwdBkwdTrgtPosCalib_TrgtPosArray: accessed-variable=Md57R3LFwdBkwdTrgtPosCalib.TrgtPosArray
              SEND_ThdRwLtStFwdBkwdEnTrigBitMask_Val: accessed-variable=ThdRwLtStFwdBkwdEnTrigBitMask.Val
              SEND_VIPR3LFwdBkwdTrgtPosCalib_TrgtPosArray: accessed-variable=VIPR3LFwdBkwdTrgtPosCalib.TrgtPosArray
          100 x parameter access:
            PA_KeSMSw6sAcsEntryThdRwLtStBkReclnUpwdDnwdPos_Val: accessed-parameter=KeSMSw6sAcsEntryThdRwLtStBkReclnUpwdDnwdPos.Val
            PA_KeSMSw6sAcsEntryThdRwLtStBkReclnUpwdDnwdPosMax_Val: accessed-parameter=KeSMSw6sAcsEntryThdRwLtStBkReclnUpwdDnwdPosMax.Val
            PA_KeSMSw6sAcsEntryThdRwLtStBkReclnUpwdDnwdPosMin_Val: accessed-parameter=KeSMSw6sAcsEntryThdRwLtStBkReclnUpwdDnwdPosMin.Val
            PA_KeSMSw6sAcsEntryThdRwLtStCshnFldUpwdDnwdPos_Val: accessed-parameter=KeSMSw6sAcsEntryThdRwLtStCshnFldUpwdDnwdPos.Val
            PA_KeSMSw6sAcsEntryThdRwLtStCshnFldUpwdDnwdPosMax_Val: accessed-parameter=KeSMSw6sAcsEntryThdRwLtStCshnFldUpwdDnwdPosMax.Val
            PA_KeSMSw6sAcsEntryThdRwLtStCshnFldUpwdDnwdPosMin_Val: accessed-parameter=KeSMSw6sAcsEntryThdRwLtStCshnFldUpwdDnwdPosMin.Val
            PA_KeSMSw6sAcsEntryThdRwLtStFrwdBkwdPos_Val: accessed-parameter=KeSMSw6sAcsEntryThdRwLtStFrwdBkwdPos.Val
            PA_KeSMSw6sAcsEntryThdRwLtStFrwdBkwdPosMax_Val: accessed-parameter=KeSMSw6sAcsEntryThdRwLtStFrwdBkwdPosMax.Val
            PA_KeSMSw6sAcsEntryThdRwLtStFrwdBkwdPosMin_Val: accessed-parameter=KeSMSw6sAcsEntryThdRwLtStFrwdBkwdPosMin.Val
            PA_KeSMSw6SAcsMd56ThdRwLtStBkReclnUpwdDnwdPos_Val: accessed-parameter=KeSMSw6SAcsMd56ThdRwLtStBkReclnUpwdDnwdPos.Val
            PA_KeSMSw6SAcsMd56ThdRwLtStBkReclnUpwdDnwdPosMax_Val: accessed-parameter=KeSMSw6SAcsMd56ThdRwLtStBkReclnUpwdDnwdPosMax.Val
            PA_KeSMSw6SAcsMd56ThdRwLtStBkReclnUpwdDnwdPosMin_Val: accessed-parameter=KeSMSw6SAcsMd56ThdRwLtStBkReclnUpwdDnwdPosMin.Val
            PA_KeSMSw6SAcsMd56ThdRwLtStFrwdBkwdPos_Val: accessed-parameter=KeSMSw6SAcsMd56ThdRwLtStFrwdBkwdPos.Val
            PA_KeSMSw6SAcsMd56ThdRwLtStFrwdBkwdPosMax_Val: accessed-parameter=KeSMSw6SAcsMd56ThdRwLtStFrwdBkwdPosMax.Val
            PA_KeSMSw6SAcsMd56ThdRwLtStFrwdBkwdPosMin_Val: accessed-parameter=KeSMSw6SAcsMd56ThdRwLtStFrwdBkwdPosMin.Val
            PA_KeSMSw6sFamilyLMdThdRwLtStFrwdBkwdPos_Val: accessed-parameter=KeSMSw6sFamilyLMdThdRwLtStFrwdBkwdPos.Val
            PA_KeSMSw6sFamilyLMdThdRwLtStFrwdBkwdPosMax_Val: accessed-parameter=KeSMSw6sFamilyLMdThdRwLtStFrwdBkwdPosMax.Val
            PA_KeSMSw6sFamilyLMdThdRwLtStFrwdBkwdPosMin_Val: accessed-parameter=KeSMSw6sFamilyLMdThdRwLtStFrwdBkwdPosMin.Val
            PA_KeSMSw6sFamilyMdThdRwLtStFrwdBkwdPos_Val: accessed-parameter=KeSMSw6sFamilyMdThdRwLtStFrwdBkwdPos.Val
            PA_KeSMSw6sFamilyMdThdRwLtStFrwdBkwdPosMax_Val: accessed-parameter=KeSMSw6sFamilyMdThdRwLtStFrwdBkwdPosMax.Val
            PA_KeSMSw6sFamilyMdThdRwLtStFrwdBkwdPosMin_Val: accessed-parameter=KeSMSw6sFamilyMdThdRwLtStFrwdBkwdPosMin.Val
            PA_KeSMSw6sLugThdRwLtStBkReclnUpwdDnwdPos_Val: accessed-parameter=KeSMSw6sLugThdRwLtStBkReclnUpwdDnwdPos.Val
            PA_KeSMSw6sLugThdRwLtStBkReclnUpwdDnwdPosMax_Val: accessed-parameter=KeSMSw6sLugThdRwLtStBkReclnUpwdDnwdPosMax.Val
            PA_KeSMSw6sLugThdRwLtStBkReclnUpwdDnwdPosMin_Val: accessed-parameter=KeSMSw6sLugThdRwLtStBkReclnUpwdDnwdPosMin.Val
            PA_KeSMSw6sLugThdRwLtStCshnFldUpwdDnwdPos_Val: accessed-parameter=KeSMSw6sLugThdRwLtStCshnFldUpwdDnwdPos.Val
            PA_KeSMSw6sLugThdRwLtStCshnFldUpwdDnwdPosMax_Val: accessed-parameter=KeSMSw6sLugThdRwLtStCshnFldUpwdDnwdPosMax.Val
            PA_KeSMSw6sLugThdRwLtStCshnFldUpwdDnwdPosMin_Val: accessed-parameter=KeSMSw6sLugThdRwLtStCshnFldUpwdDnwdPosMin.Val
            PA_KeSMSw6sLugThdRwLtStFrwdBkwdPos_Val: accessed-parameter=KeSMSw6sLugThdRwLtStFrwdBkwdPos.Val
            PA_KeSMSw6sLugThdRwLtStFrwdBkwdPosMax_Val: accessed-parameter=KeSMSw6sLugThdRwLtStFrwdBkwdPosMax.Val
            PA_KeSMSw6sLugThdRwLtStFrwdBkwdPosMin_Val: accessed-parameter=KeSMSw6sLugThdRwLtStFrwdBkwdPosMin.Val
            PA_KeSMSw6sVIPThdRwLtStBkReclnUpwdDnwdPos_Val: accessed-parameter=KeSMSw6sVIPThdRwLtStBkReclnUpwdDnwdPos.Val
            PA_KeSMSw6sVIPThdRwLtStBkReclnUpwdDnwdPosMax_Val: accessed-parameter=KeSMSw6sVIPThdRwLtStBkReclnUpwdDnwdPosMax.Val
            PA_KeSMSw6sVIPThdRwLtStBkReclnUpwdDnwdPosMin_Val: accessed-parameter=KeSMSw6sVIPThdRwLtStBkReclnUpwdDnwdPosMin.Val
            PA_KeSMSw6sVIPThdRwLtStFrwdBkwdPos_Val: accessed-parameter=KeSMSw6sVIPThdRwLtStFrwdBkwdPos.Val
            PA_KeSMSw6sVIPThdRwLtStFrwdBkwdPosMax_Val: accessed-parameter=KeSMSw6sVIPThdRwLtStFrwdBkwdPosMax.Val
            PA_KeSMSw6sVIPThdRwLtStFrwdBkwdPosMin_Val: accessed-parameter=KeSMSw6sVIPThdRwLtStFrwdBkwdPosMin.Val
            PA_KeSMSwAcsEntryThdRwLtStBkReclnUpwdDnwdPos_Val: accessed-parameter=KeSMSwAcsEntryThdRwLtStBkReclnUpwdDnwdPos.Val
            PA_KeSMSwAcsEntryThdRwLtStBkReclnUpwdDnwdPosMax_Val: accessed-parameter=KeSMSwAcsEntryThdRwLtStBkReclnUpwdDnwdPosMax.Val
            PA_KeSMSwAcsEntryThdRwLtStBkReclnUpwdDnwdPosMin_Val: accessed-parameter=KeSMSwAcsEntryThdRwLtStBkReclnUpwdDnwdPosMin.Val
            PA_KeSMSwAcsEntryThdRwLtStCshnFldUpwdDnwdPos_Val: accessed-parameter=KeSMSwAcsEntryThdRwLtStCshnFldUpwdDnwdPos.Val
            PA_KeSMSwAcsEntryThdRwLtStCshnFldUpwdDnwdPosMax_Val: accessed-parameter=KeSMSwAcsEntryThdRwLtStCshnFldUpwdDnwdPosMax.Val
            PA_KeSMSwAcsEntryThdRwLtStCshnFldUpwdDnwdPosMin_Val: accessed-parameter=KeSMSwAcsEntryThdRwLtStCshnFldUpwdDnwdPosMin.Val
            PA_KeSMSwAcsEntryThdRwLtStFrwdBkwdPos_Val: accessed-parameter=KeSMSwAcsEntryThdRwLtStFrwdBkwdPos.Val
            PA_KeSMSwAcsEntryThdRwLtStFrwdBkwdPosMax_Val: accessed-parameter=KeSMSwAcsEntryThdRwLtStFrwdBkwdPosMax.Val
            PA_KeSMSwAcsEntryThdRwLtStFrwdBkwdPosMin_Val: accessed-parameter=KeSMSwAcsEntryThdRwLtStFrwdBkwdPosMin.Val
            PA_KeSMSwAcsMd32ThdRwLtBkReclnUpwdDnwdPos_Val: accessed-parameter=KeSMSwAcsMd32ThdRwLtBkReclnUpwdDnwdPos.Val
            PA_KeSMSwAcsMd32ThdRwLtBkReclnUpwdDnwdPosMax_Val: accessed-parameter=KeSMSwAcsMd32ThdRwLtBkReclnUpwdDnwdPosMax.Val
            PA_KeSMSwAcsMd32ThdRwLtBkReclnUpwdDnwdPosMin_Val: accessed-parameter=KeSMSwAcsMd32ThdRwLtBkReclnUpwdDnwdPosMin.Val
            PA_KeSMSwAcsMd32ThdRwLtFldUpwdDnwdPos_Val: accessed-parameter=KeSMSwAcsMd32ThdRwLtFldUpwdDnwdPos.Val
            PA_KeSMSwAcsMd32ThdRwLtFldUpwdDnwdPosMax_Val: accessed-parameter=KeSMSwAcsMd32ThdRwLtFldUpwdDnwdPosMax.Val
            PA_KeSMSwAcsMd32ThdRwLtFldUpwdDnwdPosMin_Val: accessed-parameter=KeSMSwAcsMd32ThdRwLtFldUpwdDnwdPosMin.Val
            PA_KeSMSwAcsMd56ThdRwLtStBkReclnUpwdDnwdPos_Val: accessed-parameter=KeSMSwAcsMd56ThdRwLtStBkReclnUpwdDnwdPos.Val
            PA_KeSMSwAcsMd56ThdRwLtStBkReclnUpwdDnwdPosMax_Val: accessed-parameter=KeSMSwAcsMd56ThdRwLtStBkReclnUpwdDnwdPosMax.Val
            PA_KeSMSwAcsMd56ThdRwLtStBkReclnUpwdDnwdPosMin_Val: accessed-parameter=KeSMSwAcsMd56ThdRwLtStBkReclnUpwdDnwdPosMin.Val
            PA_KeSMSwAcsMd56ThdRwLtStCshnFldUpwdDnwdPos_Val: accessed-parameter=KeSMSwAcsMd56ThdRwLtStCshnFldUpwdDnwdPos.Val
            PA_KeSMSwAcsMd56ThdRwLtStCshnFldUpwdDnwdPosMax_Val: accessed-parameter=KeSMSwAcsMd56ThdRwLtStCshnFldUpwdDnwdPosMax.Val
            PA_KeSMSwAcsMd56ThdRwLtStCshnFldUpwdDnwdPosMin_Val: accessed-parameter=KeSMSwAcsMd56ThdRwLtStCshnFldUpwdDnwdPosMin.Val
            PA_KeSMSwAcsMd56ThdRwLtStFrwdBkwdPos_Val: accessed-parameter=KeSMSwAcsMd56ThdRwLtStFrwdBkwdPos.Val
            PA_KeSMSwAcsMd56ThdRwLtStFrwdBkwdPosMax_Val: accessed-parameter=KeSMSwAcsMd56ThdRwLtStFrwdBkwdPosMax.Val
            PA_KeSMSwAcsMd56ThdRwLtStFrwdBkwdPosMin_Val: accessed-parameter=KeSMSwAcsMd56ThdRwLtStFrwdBkwdPosMin.Val
            PA_KeSMSwAcsMd57ThdRwLtStBkReclnUpwdDnwdPos_Val: accessed-parameter=KeSMSwAcsMd57ThdRwLtStBkReclnUpwdDnwdPos.Val
            PA_KeSMSwAcsMd57ThdRwLtStBkReclnUpwdDnwdPosMax_Val: accessed-parameter=KeSMSwAcsMd57ThdRwLtStBkReclnUpwdDnwdPosMax.Val
            PA_KeSMSwAcsMd57ThdRwLtStBkReclnUpwdDnwdPosMin_Val: accessed-parameter=KeSMSwAcsMd57ThdRwLtStBkReclnUpwdDnwdPosMin.Val
            PA_KeSMSwAcsMd57ThdRwLtStFrwdBkwdPos_Val: accessed-parameter=KeSMSwAcsMd57ThdRwLtStFrwdBkwdPos.Val
            PA_KeSMSwAcsMd57ThdRwLtStFrwdBkwdPosMax_Val: accessed-parameter=KeSMSwAcsMd57ThdRwLtStFrwdBkwdPosMax.Val
            PA_KeSMSwAcsMd57ThdRwLtStFrwdBkwdPosMin_Val: accessed-parameter=KeSMSwAcsMd57ThdRwLtStFrwdBkwdPosMin.Val
            PA_KeSMSwAcsMd6ThdRwLtStBkReclnUpwdDnwdPos_Val: accessed-parameter=KeSMSwAcsMd6ThdRwLtStBkReclnUpwdDnwdPos.Val
            PA_KeSMSwAcsMd6ThdRwLtStBkReclnUpwdDnwdPosMax_Val: accessed-parameter=KeSMSwAcsMd6ThdRwLtStBkReclnUpwdDnwdPosMax.Val
            PA_KeSMSwAcsMd6ThdRwLtStBkReclnUpwdDnwdPosMin_Val: accessed-parameter=KeSMSwAcsMd6ThdRwLtStBkReclnUpwdDnwdPosMin.Val
            PA_KeSMSwAcsMd6ThdRwLtStCshnFldUpwdDnwdPos_Val: accessed-parameter=KeSMSwAcsMd6ThdRwLtStCshnFldUpwdDnwdPos.Val
            PA_KeSMSwAcsMd6ThdRwLtStCshnFldUpwdDnwdPosMax_Val: accessed-parameter=KeSMSwAcsMd6ThdRwLtStCshnFldUpwdDnwdPosMax.Val
            PA_KeSMSwAcsMd6ThdRwLtStCshnFldUpwdDnwdPosMin_Val: accessed-parameter=KeSMSwAcsMd6ThdRwLtStCshnFldUpwdDnwdPosMin.Val
            PA_KeSMSwAcsMd6ThdRwLtStFrwdBkwdPos_Val: accessed-parameter=KeSMSwAcsMd6ThdRwLtStFrwdBkwdPos.Val
            PA_KeSMSwAcsMd6ThdRwLtStFrwdBkwdPosMax_Val: accessed-parameter=KeSMSwAcsMd6ThdRwLtStFrwdBkwdPosMax.Val
            PA_KeSMSwAcsMd6ThdRwLtStFrwdBkwdPosMin_Val: accessed-parameter=KeSMSwAcsMd6ThdRwLtStFrwdBkwdPosMin.Val
            PA_KeSMSwFamilyLMdThdRwLtStFrwdBkwdPos_Val: accessed-parameter=KeSMSwFamilyLMdThdRwLtStFrwdBkwdPos.Val
            PA_KeSMSwFamilyLMdThdRwLtStFrwdBkwdPosMax_Val: accessed-parameter=KeSMSwFamilyLMdThdRwLtStFrwdBkwdPosMax.Val
            PA_KeSMSwFamilyLMdThdRwLtStFrwdBkwdPosMin_Val: accessed-parameter=KeSMSwFamilyLMdThdRwLtStFrwdBkwdPosMin.Val
            PA_KeSMSwFamilyMdThdRwLtStFrwdBkwdPos_Val: accessed-parameter=KeSMSwFamilyMdThdRwLtStFrwdBkwdPos.Val
            PA_KeSMSwFamilyMdThdRwLtStFrwdBkwdPosMax_Val: accessed-parameter=KeSMSwFamilyMdThdRwLtStFrwdBkwdPosMax.Val
            PA_KeSMSwFamilyMdThdRwLtStFrwdBkwdPosMin_Val: accessed-parameter=KeSMSwFamilyMdThdRwLtStFrwdBkwdPosMin.Val
            PA_KeSMSwLugThdRwLtStBkReclnUpwdDnwdPos_Val: accessed-parameter=KeSMSwLugThdRwLtStBkReclnUpwdDnwdPos.Val
            PA_KeSMSwLugThdRwLtStBkReclnUpwdDnwdPosMax_Val: accessed-parameter=KeSMSwLugThdRwLtStBkReclnUpwdDnwdPosMax.Val
            PA_KeSMSwLugThdRwLtStBkReclnUpwdDnwdPosMin_Val: accessed-parameter=KeSMSwLugThdRwLtStBkReclnUpwdDnwdPosMin.Val
            PA_KeSMSwLugThdRwLtStCshnFldUpwdDnwdPos_Val: accessed-parameter=KeSMSwLugThdRwLtStCshnFldUpwdDnwdPos.Val
            PA_KeSMSwLugThdRwLtStCshnFldUpwdDnwdPosMax_Val: accessed-parameter=KeSMSwLugThdRwLtStCshnFldUpwdDnwdPosMax.Val
            PA_KeSMSwLugThdRwLtStCshnFldUpwdDnwdPosMin_Val: accessed-parameter=KeSMSwLugThdRwLtStCshnFldUpwdDnwdPosMin.Val
            PA_KeSMSwLugThdRwLtStFrwdBkwdPos_Val: accessed-parameter=KeSMSwLugThdRwLtStFrwdBkwdPos.Val
            PA_KeSMSwLugThdRwLtStFrwdBkwdPosMax_Val: accessed-parameter=KeSMSwLugThdRwLtStFrwdBkwdPosMax.Val
            PA_KeSMSwLugThdRwLtStFrwdBkwdPosMin_Val: accessed-parameter=KeSMSwLugThdRwLtStFrwdBkwdPosMin.Val
            PA_KeSMSwThdRwLtStBkReclnEnTrigBitMask_Val: accessed-parameter=KeSMSwThdRwLtStBkReclnEnTrigBitMask.Val
            PA_KeSMSwThdRwLtStBkReclnEnTrigBitMask6s_Val: accessed-parameter=KeSMSwThdRwLtStBkReclnEnTrigBitMask6s.Val
            PA_KeSMSwThdRwLtStFwdBkwdEnTrigBitMask_Val: accessed-parameter=KeSMSwThdRwLtStFwdBkwdEnTrigBitMask.Val
            PA_KeSMSwThdRwLtStFwdBkwdEnTrigBitMask6s_Val: accessed-parameter=KeSMSwThdRwLtStFwdBkwdEnTrigBitMask6s.Val
            PA_KeSMSwVIPThdRwLtStBkReclnUpwdDnwdPos_Val: accessed-parameter=KeSMSwVIPThdRwLtStBkReclnUpwdDnwdPos.Val
            PA_KeSMSwVIPThdRwLtStBkReclnUpwdDnwdPosMax_Val: accessed-parameter=KeSMSwVIPThdRwLtStBkReclnUpwdDnwdPosMax.Val
            PA_KeSMSwVIPThdRwLtStBkReclnUpwdDnwdPosMin_Val: accessed-parameter=KeSMSwVIPThdRwLtStBkReclnUpwdDnwdPosMin.Val
            PA_KeSMSwVIPThdRwLtStFrwdBkwdPos_Val: accessed-parameter=KeSMSwVIPThdRwLtStFrwdBkwdPos.Val
            PA_KeSMSwVIPThdRwLtStFrwdBkwdPosMax_Val: accessed-parameter=KeSMSwVIPThdRwLtStFrwdBkwdPosMax.Val
            PA_KeSMSwVIPThdRwLtStFrwdBkwdPosMin_Val: accessed-parameter=KeSMSwVIPThdRwLtStFrwdBkwdPosMin.Val
  swc implementation ThdRwLtStCalib_Implementation: behavior=ThdRwLtStCalib_InternalBehavior
    code-descriptors:
      code Default: artifact-descriptors=autosar-engineering-object={short-label=Default, category=SWSRC}
package /PATAC/MSM/ModeAdjust/CalPortInterface
  parameter interface Pos
    parameter data prototype Val: sw-calibration-access=READ-WRITE, type=UInt16
  parameter interface StEnTrigBitMask
    parameter data prototype Val: sw-calibration-access=READ-WRITE, type=UInt32
package /PATAC/MSM/ModeAdjust/DataType
  impl type TrgtPosCalibArray: category=ARRAY, sw-calibration-access=READ-ONLY, type-emitter=RTE  # 0:pos 1:max 2:min
    element Element: array-size=3, array-size-semantics=FIXED-SIZE, implementation-data-type=UInt16, invalid-value=0
package /PATAC/MSM/ModeAdjust/Interfaces
  sender receiver interface IfVeSMSuThdRwLtStCshnFldUpwdDnwdPos: invalidation-policy{data-element=IfVeSMSuThdRwLtStCshnFldUpwdDnwdPos/Val, handle-invalid=DONT-INVALIDATE}
    data Val: type=UInt16
package /PATAC/MSM/ModeAdjust/PortInterface
  6 x client server interface:
    Md58TrgtPos
      operation Get
        12 x arg, all with type=UInt16, direction=OUT, server-argument-impl-policy=USE-ARGUMENT-TYPE:
          SecRwRtStBkReclnTrgtPos
          SecRwRtStZeroTrgtPos
          SecRwRtStLgrstUpwdDnwdTrgtPos
          SecRwRtStLgrstInwdOtwdTrgtPos
          ThdRwLtStBkReclnTrgtPos
          ThdRwLtStFwdBkwdTrgtPos
          ThdRwRtStBkReclnTrgtPos
          ThdRwRtStFwdBkwdTrgtPos
          PassStBkReclnTrgtPos
          PassStFwdBkwdTrgtPos
          SecRwRtStFwdBkwdTrgtPos
          PassStFldTrgtPos
      operation Set
    ThdRwLtStBkReclnTrgtPosSelc
      operation Cal
    ThdRwLtStCshnFldTrgtPosSelc
      operation Cal
    ThdRwLtStFwdBkwdTrgtPosSelc
      operation Cal
    VIPLExit557TrgtPos
      operation Get
        7 x arg, all with type=UInt16, direction=OUT, server-argument-impl-policy=USE-ARGUMENT-TYPE:
          SecRwLtStBkReclnTrgtPos
          SecRwLtStZeroTrgtPos
          SecRwLtStLgrstUpwdDnwdTrgtPos
          SecRwLtStLgrstInwdOtwdTrgtPos
          ThdRwLtStBkReclnTrgtPos
          ThdRwLtStFwdBkwdTrgtPos
          SecRwLtStFwdBkwdTrgtPos
      operation Set
    VIPRExit557TrgtPos
      operation Get
        11 x arg, all with type=UInt16, direction=OUT, server-argument-impl-policy=USE-ARGUMENT-TYPE:
          SecRwRtStBkReclnTrgtPos
          SecRwRtStZeroTrgtPos
          SecRwRtStLgrstUpwdDnwdTrgtPos
          SecRwRtStLgrstInwdOtwdTrgtPos
          ThdRwLtStBkReclnTrgtPos
          ThdRwLtStFwdBkwdTrgtPos
          ThdRwRtStBkReclnTrgtPos
          ThdRwRtStFwdBkwdTrgtPos
          PassStBkReclnTrgtPos
          PassStFwdBkwdTrgtPos
          SecRwRtStFwdBkwdTrgtPos
      operation Set
  sender receiver interface StEnTrigBitMask: invalidation-policy{data-element=StEnTrigBitMask/Val, handle-invalid=DONT-INVALIDATE}
    data Val: type=UInt32
  sender receiver interface StNumFlg
    4 x data, all with type=Boolean:
      Is4s
      Is6s
      Is6s7s
      Is7s
    invalidation-policys:
      data-element=Is4s, handle-invalid=DONT-INVALIDATE
      data-element=Is6s, handle-invalid=DONT-INVALIDATE
      data-element=Is6s7s, handle-invalid=DONT-INVALIDATE
      data-element=Is7s, handle-invalid=DONT-INVALIDATE
  sender receiver interface TrgtPosCalibArray: invalidation-policy{data-element=TrgtPosArray, handle-invalid=DONT-INVALIDATE}
    data TrgtPosArray: type=TrgtPosCalibArray  # 0:Pos 1:Max 2:Min
